VERSION ""

NS_ :

BS_:

BU_: ExternalDevice EMUS_BMS
BU_: INV U2C VCU BMS
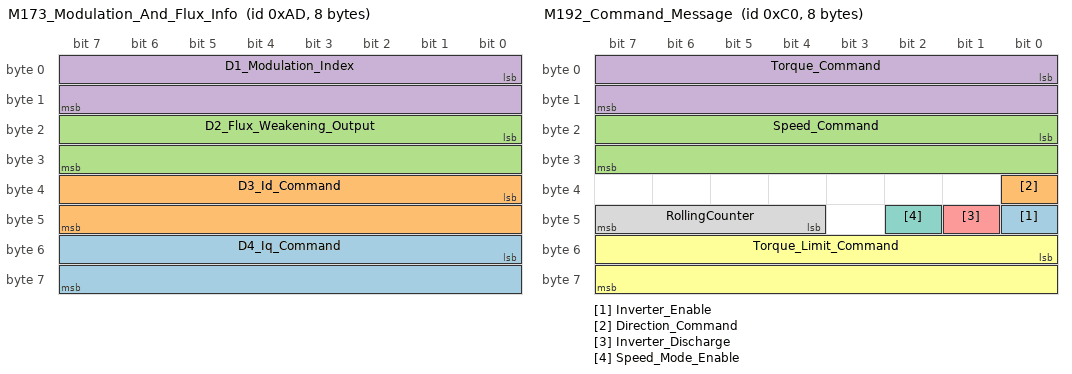
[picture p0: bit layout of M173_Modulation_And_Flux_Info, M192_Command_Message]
BO_ 173 M173_Modulation_And_Flux_Info: 8 INV
 SG_ D4_Iq_Command : 48|16@1- (0.1,0) [-3276.8|3276.7] "A" Vector__XXX
 SG_ D3_Id_Command : 32|16@1- (0.1,0) [-3276.8|3276.7] "A" Vector__XXX
 SG_ D2_Flux_Weakening_Output : 16|16@1- (0.1,0) [-3276.8|3276.7] "A" Vector__XXX
 SG_ D1_Modulation_Index : 0|16@1- (0.0001,0) [-3.2768|3.2767] "" Vector__XXX

BO_ 172 M172_Torque_And_Timer_Info: 8 INV
 SG_ D3_Power_On_Timer : 32|32@1+ (0.003,0) [0|12884800] "Sec" Vector__XXX
 SG_ D2_Torque_Feedback : 16|16@1- (0.1,0) [-3276.8|3276.7] "Nm" Vector__XXX
 SG_ D1_Commanded_Torque : 0|16@1- (0.1,0) [-3276.8|3276.7] "Nm" Vector__XXX

BO_ 194 M194_Read_Write_Param_Response: 8 INV
 SG_ D2_Write_Success : 16|1@1+ (1,0) [0|1] "" Vector__XXX
 SG_ D3_Data_Response : 32|16@1- (1,0) [-32768|32767] "" Vector__XXX
 SG_ D1_Parameter_Address_Response : 0|16@1+ (1,0) [0|65535] "" Vector__XXX

BO_ 193 M193_Read_Write_Param_Command: 8 VCU
 SG_ D3_Data_Command : 32|16@1- (1,0) [-32768|32767] "" Vector__XXX
 SG_ D2_Read_Write_Command : 16|1@1+ (1,0) [0|1] "" Vector__XXX
 SG_ D1_Parameter_Address_Command : 0|16@1+ (1,0) [0|65535] "" Vector__XXX

BO_ 192 M192_Command_Message: 8 VCU
 SG_ Inverter_Enable : 40|1@1+ (1,0) [0|1] "Bit" Vector__XXX
 SG_ Direction_Command : 32|1@1+ (1,0) [0|1] "Bit" Vector__XXX
 SG_ Speed_Command : 16|16@1- (1,0) [-32768|32767] "rpm" Vector__XXX
 SG_ Torque_Command : 0|16@1- (0.1,0) [-3276.8|3276.7] "Nm" Vector__XXX
 SG_ Inverter_Discharge : 41|1@1+ (1,0) [0|1] "Bit" Vector__XXX
 SG_ Torque_Limit_Command : 48|16@1- (0.1,0) [-3276.8|3276.7] "Nm" Vector__XXX
 SG_ Speed_Mode_Enable : 42|1@1+ (1,0) [0|1] "Bit" Vector__XXX
 SG_ RollingCounter : 44|4@1+ (1,0) [0|15] "Bits" Vector__XXX

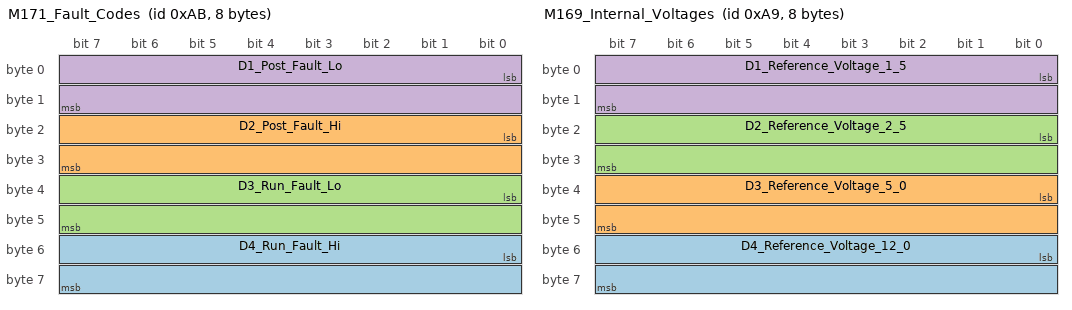
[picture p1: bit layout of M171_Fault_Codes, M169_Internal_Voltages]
BO_ 171 M171_Fault_Codes: 8 INV
 SG_ D4_Run_Fault_Hi : 48|16@1+ (1,0) [0|65535] "" Vector__XXX
 SG_ D2_Post_Fault_Hi : 16|16@1+ (1,0) [0|65535] "" Vector__XXX
 SG_ D3_Run_Fault_Lo : 32|16@1+ (1,0) [0|65535] "" Vector__XXX
 SG_ D1_Post_Fault_Lo : 0|16@1+ (1,0) [0|65535] "" Vector__XXX

BO_ 170 M170_Internal_States: 8 INV
 SG_ D7_Direction_Command : 56|1@1+ (1,0) [0|1] "" Vector__XXX
 SG_ D6_Inverter_Enable_State : 48|1@1+ (1,0) [0|1] "" Vector__XXX
 SG_ D3_Relay_3_Status : 26|1@1+ (1,0) [0|1] "" Vector__XXX
 SG_ D3_Relay_4_Status : 27|1@1+ (1,0) [0|1] "" Vector__XXX
 SG_ D3_Relay_2_Status : 25|1@1+ (1,0) [0|1] "" Vector__XXX
 SG_ D4_Inverter_Run_Mode : 32|1@1+ (1,0) [0|1] "" Vector__XXX
 SG_ D5_Inverter_Command_Mode : 40|1@1+ (1,0) [0|1] "" Vector__XXX
 SG_ D3_Relay_1_Status : 24|1@1+ (1,0) [0|1] "" Vector__XXX
 SG_ D2_Inverter_State : 16|8@1+ (1,0) [0|255] "" Vector__XXX
 SG_ D1_VSM_State : 0|8@1+ (1,0) [0|15] "" Vector__XXX
 SG_ D6_Inverter_Enable_Lockout : 55|1@1+ (1,0) [0|1] "" Vector__XXX
 SG_ D4_Inverter_Discharge_State : 37|3@1+ (1,0) [0|7] "" Vector__XXX
 SG_ D3_Relay_5_Status : 28|1@1+ (1,0) [0|1] "" Vector__XXX
 SG_ D3_Relay_6_Status : 29|1@1+ (1,0) [0|1] "" Vector__XXX
 SG_ D7_BMS_Active : 57|1@1+ (1,0) [0|1] "" Vector__XXX
 SG_ D7_BMS_Torque_Limiting : 58|1@1+ (1,0) [0|1] "" Vector__XXX
 SG_ D7_Max_Speed_Limiting : 59|1@1+ (1,0) [0|1] "" Vector__XXX
 SG_ D7_Low_Speed_Limiting : 61|1@1+ (1,0) [0|1] "" Vector__XXX
 SG_ D5_Rolling_Counter : 44|4@1+ (1,0) [0|15] "" Vector__XXX
 SG_ D1_PWM_Frequency : 8|8@1+ (1,0) [0|255] "kHz" Vector__XXX
 SG_ D6_Start_Mode_Active : 54|1@1+ (1,0) [0|1] "" Vector__XXX

BO_ 169 M169_Internal_Voltages: 8 INV
 SG_ D4_Reference_Voltage_12_0 : 48|16@1- (0.01,0) [-327.68|327.67] "V" Vector__XXX
 SG_ D3_Reference_Voltage_5_0 : 32|16@1- (0.01,0) [-327.68|327.67] "V" Vector__XXX
 SG_ D2_Reference_Voltage_2_5 : 16|16@1- (0.01,0) [-327.68|327.67] "V" Vector__XXX
 SG_ D1_Reference_Voltage_1_5 : 0|16@1- (0.01,0) [-327.68|327.67] "V" Vector__XXX

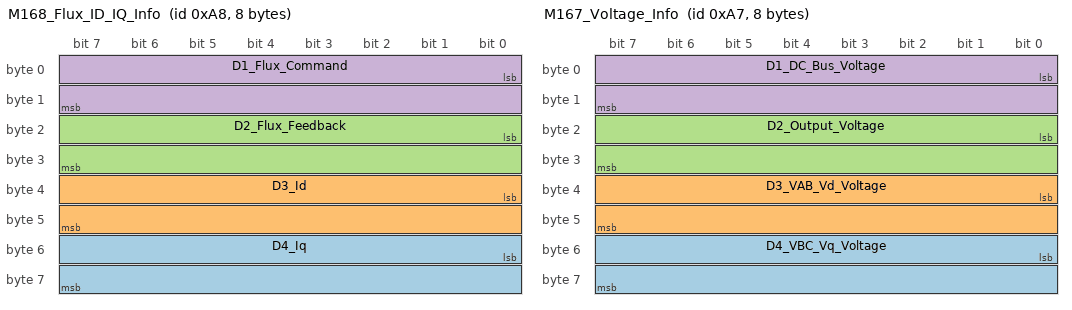
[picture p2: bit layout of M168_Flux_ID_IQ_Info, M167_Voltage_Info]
BO_ 168 M168_Flux_ID_IQ_Info: 8 INV
 SG_ D4_Iq : 48|16@1- (0.1,0) [-3276.8|3276.7] "A" Vector__XXX
 SG_ D3_Id : 32|16@1- (0.1,0) [-3276.8|3276.7] "A" Vector__XXX
 SG_ D2_Flux_Feedback : 16|16@1- (0.001,0) [-32.768|32.767] "Wb" Vector__XXX
 SG_ D1_Flux_Command : 0|16@1- (0.001,0) [-32.768|32.767] "Wb" Vector__XXX

BO_ 167 M167_Voltage_Info: 8 INV
 SG_ D4_VBC_Vq_Voltage : 48|16@1- (0.1,0) [-3276.8|3276.7] "V" Vector__XXX
 SG_ D3_VAB_Vd_Voltage : 32|16@1- (0.1,0) [-3276.8|3276.7] "V" Vector__XXX
 SG_ D2_Output_Voltage : 16|16@1- (0.1,0) [-3276.8|3276.7] "V" Vector__XXX
 SG_ D1_DC_Bus_Voltage : 0|16@1- (0.1,0) [-3276.8|3276.7] "V" Vector__XXX

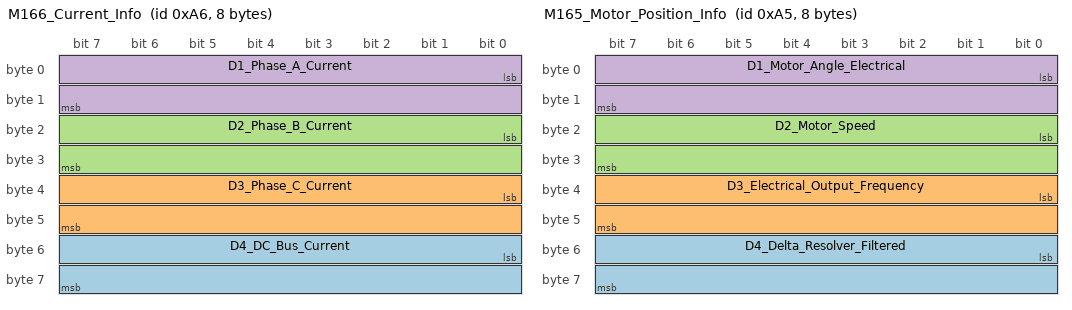
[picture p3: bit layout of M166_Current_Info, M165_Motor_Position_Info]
BO_ 166 M166_Current_Info: 8 INV
 SG_ D4_DC_Bus_Current : 48|16@1- (0.1,0) [-3276.8|3276.7] "A" Vector__XXX
 SG_ D3_Phase_C_Current : 32|16@1- (0.1,0) [-3276.8|3276.7] "A" Vector__XXX
 SG_ D2_Phase_B_Current : 16|16@1- (0.1,0) [-3276.8|3276.7] "A" Vector__XXX
 SG_ D1_Phase_A_Current : 0|16@1- (0.1,0) [-3276.8|3276.7] "A" Vector__XXX

BO_ 165 M165_Motor_Position_Info: 8 INV
 SG_ D4_Delta_Resolver_Filtered : 48|16@1- (0.1,0) [-3276.8|3276.7] "deg" Vector__XXX
 SG_ D3_Electrical_Output_Frequency : 32|16@1- (0.1,0) [-3276.8|3276.7] "hz" Vector__XXX
 SG_ D2_Motor_Speed : 16|16@1- (1,0) [-32768|32767] "rpm" Vector__XXX
 SG_ D1_Motor_Angle_Electrical : 0|16@1+ (0.1,0) [0|6553.5] "deg" Vector__XXX

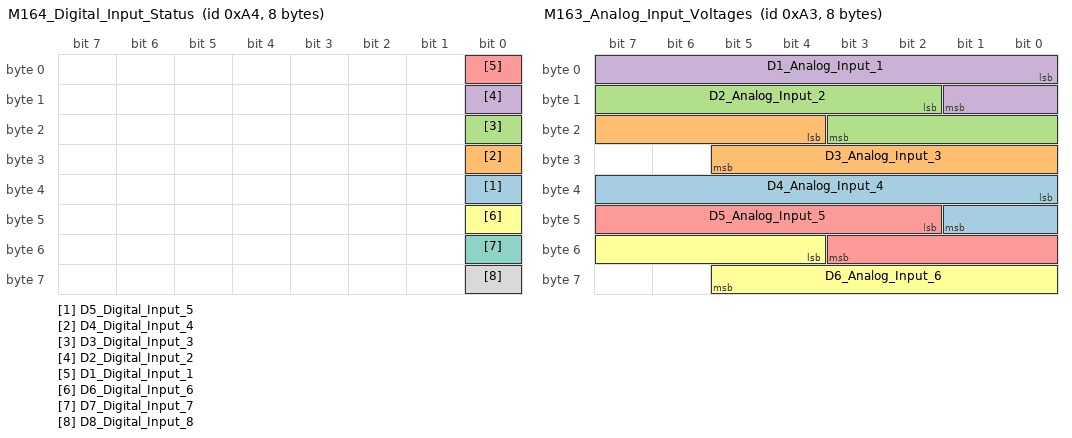
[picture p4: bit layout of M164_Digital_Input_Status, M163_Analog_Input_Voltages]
BO_ 164 M164_Digital_Input_Status: 8 INV
 SG_ D5_Digital_Input_5 : 32|1@1+ (1,0) [0|1] "boolean" Vector__XXX
 SG_ D4_Digital_Input_4 : 24|1@1+ (1,0) [0|1] "boolean" Vector__XXX
 SG_ D3_Digital_Input_3 : 16|1@1+ (1,0) [0|1] "boolean" Vector__XXX
 SG_ D2_Digital_Input_2 : 8|1@1+ (1,0) [0|1] "boolean" Vector__XXX
 SG_ D1_Digital_Input_1 : 0|1@1+ (1,0) [0|1] "boolean" Vector__XXX
 SG_ D6_Digital_Input_6 : 40|1@1+ (1,0) [0|1] "boolean" Vector__XXX
 SG_ D7_Digital_Input_7 : 48|1@1+ (1,0) [0|1] "boolean" Vector__XXX
 SG_ D8_Digital_Input_8 : 56|1@1+ (1,0) [0|1] "boolean" Vector__XXX

BO_ 163 M163_Analog_Input_Voltages: 8 INV
 SG_ D4_Analog_Input_4 : 32|10@1+ (0.01,0) [0|10.23] "V" Vector__XXX
 SG_ D3_Analog_Input_3 : 20|10@1+ (0.01,0) [0|10.23] "V" Vector__XXX
 SG_ D2_Analog_Input_2 : 10|10@1+ (0.01,0) [0|10.23] "V" Vector__XXX
 SG_ D1_Analog_Input_1 : 0|10@1+ (0.01,0) [0|10.23] "V" Vector__XXX
 SG_ D5_Analog_Input_5 : 42|10@1+ (0.01,0) [0|10.23] "V" Vector__XXX
 SG_ D6_Analog_Input_6 : 52|10@1+ (0.01,0) [0|10.23] "V" Vector__XXX

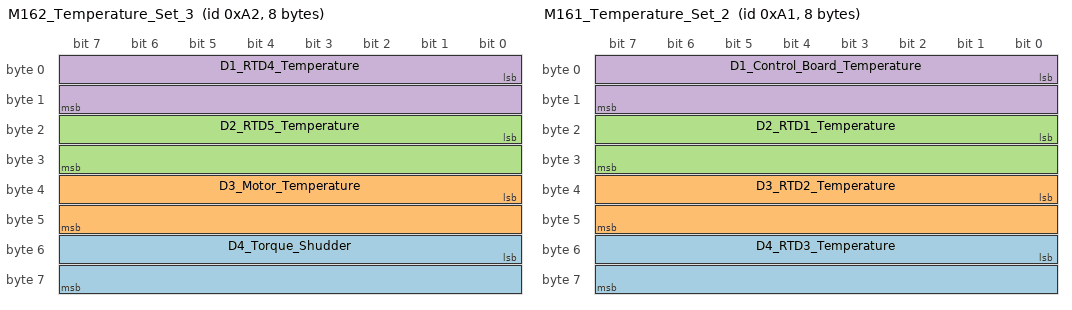
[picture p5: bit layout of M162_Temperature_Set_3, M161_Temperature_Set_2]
BO_ 162 M162_Temperature_Set_3: 8 INV
 SG_ D4_Torque_Shudder : 48|16@1- (0.1,0) [-3276.8|3276.7] "Nm" Vector__XXX
 SG_ D3_Motor_Temperature : 32|16@1- (0.1,0) [-3276.8|3276.7] "degC" Vector__XXX
 SG_ D2_RTD5_Temperature : 16|16@1- (0.1,0) [-3276.8|3276.7] "degC" Vector__XXX
 SG_ D1_RTD4_Temperature : 0|16@1- (0.1,0) [-3276.8|3276.7] "degC" Vector__XXX

BO_ 161 M161_Temperature_Set_2: 8 INV
 SG_ D4_RTD3_Temperature : 48|16@1- (0.1,0) [-3276.8|3276.7] "degC" Vector__XXX
 SG_ D3_RTD2_Temperature : 32|16@1- (0.1,0) [-3276.8|3276.7] "degC" Vector__XXX
 SG_ D2_RTD1_Temperature : 16|16@1- (0.1,0) [-3276.8|3276.7] "degC" Vector__XXX
 SG_ D1_Control_Board_Temperature : 0|16@1- (0.1,0) [-3276.8|3276.7] "degC" Vector__XXX

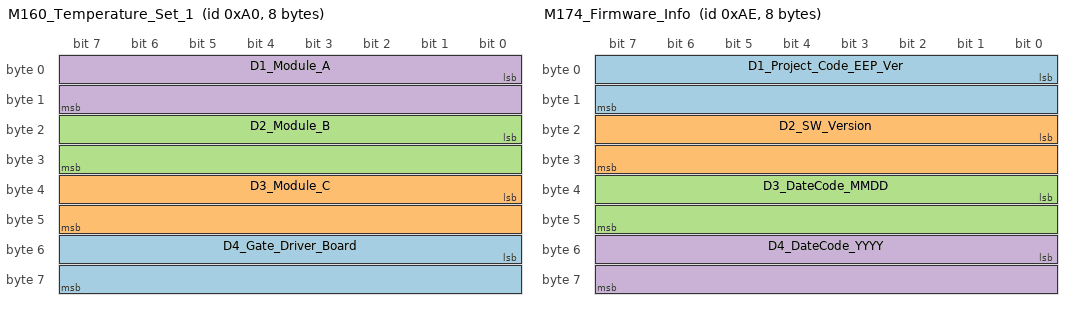
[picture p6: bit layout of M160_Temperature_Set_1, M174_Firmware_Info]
BO_ 160 M160_Temperature_Set_1: 8 INV
 SG_ D4_Gate_Driver_Board : 48|16@1- (0.1,0) [-3276.8|3276.7] "degC" Vector__XXX
 SG_ D3_Module_C : 32|16@1- (0.1,0) [-3276.8|3276.7] "degC" Vector__XXX
 SG_ D2_Module_B : 16|16@1- (0.1,0) [-3276.8|3276.7] "degC" Vector__XXX
 SG_ D1_Module_A : 0|16@1- (0.1,0) [-3276.8|3276.7] "degC" Vector__XXX

BO_ 174 M174_Firmware_Info: 8 INV
 SG_ D1_Project_Code_EEP_Ver : 0|16@1+ (1,0) [0|65535] "" Vector__XXX
 SG_ D2_SW_Version : 16|16@1+ (1,0) [0|65535] "" Vector__XXX
 SG_ D3_DateCode_MMDD : 32|16@1+ (1,0) [0|65535] "" Vector__XXX
 SG_ D4_DateCode_YYYY : 48|16@1+ (1,0) [0|65535] "" Vector__XXX

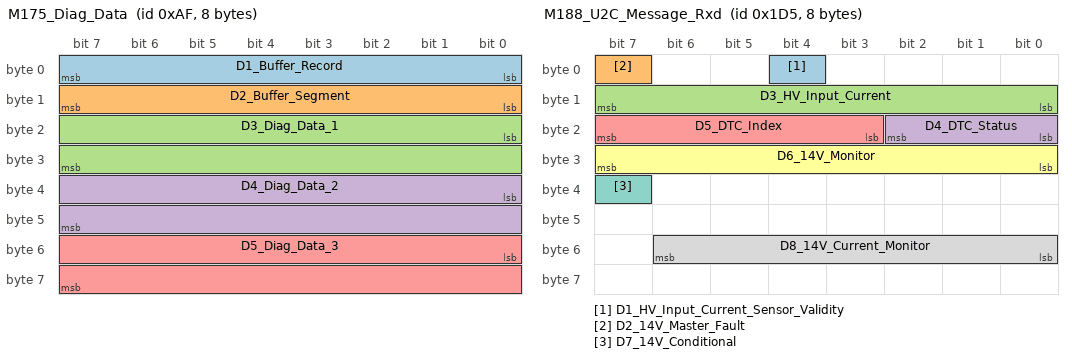
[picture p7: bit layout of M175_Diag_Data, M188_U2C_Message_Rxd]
BO_ 175 M175_Diag_Data: 8 INV
 SG_ D1_Buffer_Record : 0|8@1+ (1,0) [0|255] "" Vector__XXX
 SG_ D2_Buffer_Segment : 8|8@1+ (1,0) [0|5] "" Vector__XXX
 SG_ D3_Diag_Data_1 : 16|16@1- (1,0) [-32768|32767] "" Vector__XXX
 SG_ D4_Diag_Data_2 : 32|16@1- (1,0) [-32768|32767] "" Vector__XXX
 SG_ D5_Diag_Data_3 : 48|16@1- (1,0) [-32768|32767] "" Vector__XXX

BO_ 471 M187_U2C_Command_Txd: 8 INV
 SG_ D1_ID_Byte : 0|8@1+ (1,0) [0|255] "" Vector__XXX
 SG_ D2_Setpoint_Calc : 8|8@1+ (1,0) [0|255] "" Vector__XXX

BO_ 469 M188_U2C_Message_Rxd: 8 U2C
 SG_ D1_HV_Input_Current_Sensor_Validity : 4|1@1+ (1,0) [0|1] "" Vector__XXX
 SG_ D2_14V_Master_Fault : 7|1@1+ (1,0) [0|1] "" Vector__XXX
 SG_ D3_HV_Input_Current : 8|8@1+ (1,0) [0|255] "" Vector__XXX
 SG_ D4_DTC_Status : 16|3@1+ (1,0) [0|7] "" Vector__XXX
 SG_ D5_DTC_Index : 19|5@1+ (1,0) [0|31] "" Vector__XXX
 SG_ D6_14V_Monitor : 24|8@1+ (1,0) [0|255] "" Vector__XXX
 SG_ D7_14V_Conditional : 39|1@1+ (1,0) [0|1] "" Vector__XXX
 SG_ D8_14V_Current_Monitor : 48|7@1+ (1,0) [0|127] "" Vector__XXX

BO_ 514 BMS_Current_Limit: 8 BMS
 SG_ D1_Max_Discharge_Current : 0|16@1+ (1,0) [0|1000] "A" Vector__XXX
 SG_ D2_Max_Charge_Current : 16|16@1+ (1,0) [0|1000] "A" Vector__XXX

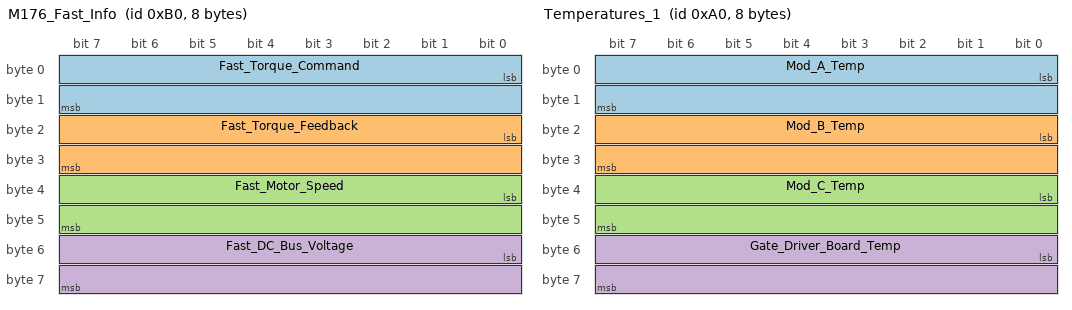
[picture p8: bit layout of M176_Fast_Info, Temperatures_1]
BO_ 176 M176_Fast_Info: 8 INV
 SG_ Fast_Torque_Command : 0|16@1- (0.1,0) [-3276.8|3276.7] "Nm" Vector__XXX
 SG_ Fast_Torque_Feedback : 16|16@1- (0.1,0) [-3276.8|3276.7] "Nm" Vector__XXX
 SG_ Fast_Motor_Speed : 32|16@1- (1,0) [-32768|32767] "rpm" Vector__XXX
 SG_ Fast_DC_Bus_Voltage : 48|16@1- (0.1,0) [-3276.8|3276.7] "V" Vector__XXX

BO_ 160 Temperatures_1: 8 Vector__XXX
	SG_ Mod_A_Temp : 0|16@1- (0.1,0) [-3276.8|3276.7] "C" Vector__XXX
	SG_ Mod_B_Temp : 16|16@1- (0.1,0) [-3276.8|3276.7] "C" Vector__XXX
	SG_ Mod_C_Temp : 32|16@1- (0.1,0) [-3276.8|3276.7] "C" Vector__XXX
	SG_ Gate_Driver_Board_Temp : 48|16@1- (0.1,0) [-3276.8|3276.7] "C" Vector__XXX

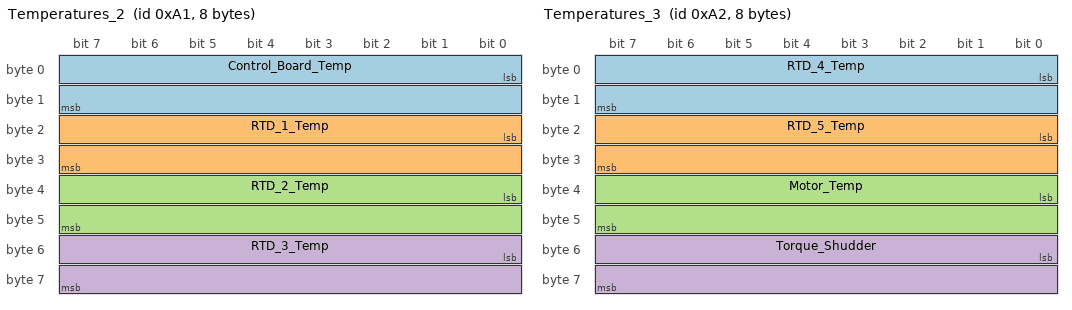
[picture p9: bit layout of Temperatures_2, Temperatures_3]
BO_ 161 Temperatures_2: 8 Vector__XXX
	SG_ Control_Board_Temp : 0|16@1- (0.1,0) [-3276.8|3276.7] "C" Vector__XXX
	SG_ RTD_1_Temp : 16|16@1- (0.1,0) [-3276.8|3276.7] "C" Vector__XXX
	SG_ RTD_2_Temp : 32|16@1- (0.1,0) [-3276.8|3276.7] "C" Vector__XXX
	SG_ RTD_3_Temp : 48|16@1- (0.1,0) [-3276.8|3276.7] "C" Vector__XXX

BO_ 162 Temperatures_3: 8 Vector__XXX
	SG_ RTD_4_Temp : 0|16@1- (0.1,0) [-3276.8|3276.7] "C" Vector__XXX
	SG_ RTD_5_Temp : 16|16@1- (0.1,0) [-3276.8|3276.7] "C" Vector__XXX
	SG_ Motor_Temp : 32|16@1- (0.1,0) [-3276.8|3276.7] "C" Vector__XXX
	SG_ Torque_Shudder : 48|16@1- (0.1,0) [-3276.8|3276.7] "N*m" Vector__XXX

BO_ 165 Motor_Position_Info: 8 Vector__XXX
	SG_ Motor_Angle_Electrical : 0|16@1- (0.1,0) [-359.9|359.9] "degrees" Vector__XXX
	SG_ Motor_Speed : 16|16@1- (0.1,0) [-32768|32767] "rpm" Vector__XXX
	SG_ Electrical_Output_Freq : 32|16@1- (0.1,0) [-3276.8|3276.7] "Hz" Vector__XXX
	SG_ Delta_Resolver_Filtered : 48|16@1- (0.1,0) [-359.9|359.9] "degrees" Vector__XXX

BO_ 2148139011 Accelerometer: 6 Vector__XXX
	SG_ X_Axis_Acceleration : 7|16@0- (0.000244141,0) [-8|8] "g" Vector__XXX
	SG_ Y_Axis_Acceleration : 23|16@0- (0.000244141,0) [-8|8] "g" Vector__XXX
	SG_ Z_Axis_Acceleration : 39|16@0- (0.000244141,0) [-8|8] "g" Vector__XXX

BO_ 2148139012 Yaw_Rate: 6 Vector__XXX
	SG_ X_Axis_YawRate : 7|16@0- (0.015258789,0) [-500|500] "deg/s" Vector__XXX
	SG_ Y_Axis_YawRate : 23|16@0- (0.015258789,0) [-500|500] "deg/s" Vector__XXX
	SG_ Z_Axis_YawRate : 39|16@0- (0.015258789,0) [-500|500] "deg/s" Vector__XXX

BO_ 2148139008 GPS_Position: 8 Vector__XXX
	SG_ GPS_Latitude : 7|32@0- (1,0) [-180|180] "degrees" Vector__XXX
	SG_ GPS_Longitude : 39|32@0- (1,0) [-180|180] "degrees" Vector__XXX

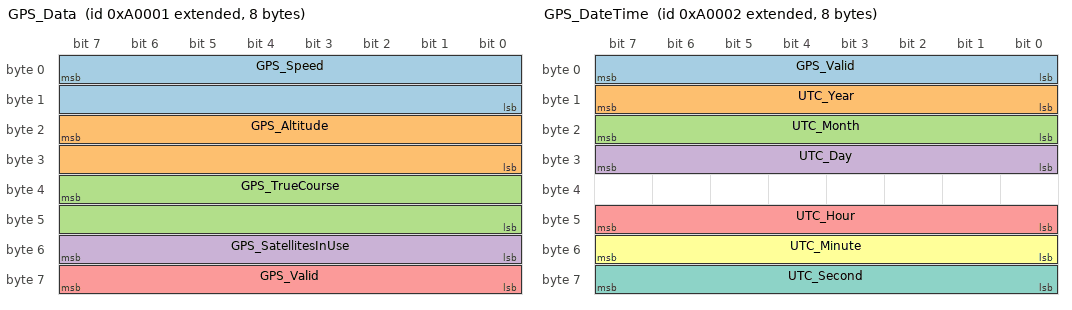
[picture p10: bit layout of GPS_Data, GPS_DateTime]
BO_ 2148139009 GPS_Data: 8 Vector__XXX
	SG_ GPS_Speed : 7|16@0+ (0.01,0) [0|655.35] "mph" Vector__XXX
	SG_ GPS_Altitude : 23|16@0- (1,0) [-32768|32767] "ft" Vector__XXX
	SG_ GPS_TrueCourse : 39|16@0+ (0.01,0) [0|655.35] "degrees" Vector__XXX
	SG_ GPS_SatellitesInUse : 55|8@0+ (1,0) [0|255] "satellites" Vector__XXX
	SG_ GPS_Valid : 63|8@0+ (1,0) [0|255] "OK(1)/N(2)" Vector__XXX

BO_ 2148139010 GPS_DateTime: 8 Vector__XXX
	SG_ GPS_Valid : 7|8@0+ (1,0) [0|255] "OK(1)/N(2)" Vector__XXX
	SG_ UTC_Year : 15|8@0+ (1,0) [0|255] "year" Vector__XXX
	SG_ UTC_Month : 23|8@0+ (1,0) [0|255] "month" Vector__XXX
	SG_ UTC_Day : 31|8@0+ (1,0) [0|255] "day" Vector__XXX
	SG_ UTC_Hour : 47|8@0+ (1,0) [0|255] "hour" Vector__XXX
	SG_ UTC_Minute : 55|8@0+ (1,0) [0|255] "min" Vector__XXX
	SG_ UTC_Second : 63|8@0+ (1,0) [0|255] "sec" Vector__XXX

BU_: ExternalDevice EMUS_BMS

BO_ 2578777872 Serial_Number_Ext: 4 EMUS_BMS
 SG_ Serial_Number_Number : 7|32@0+ (1,0) [0|4294967295] "" Vector__XXX

BO_ 3 Serial_Number_Std: 4 EMUS_BMS
 SG_ Serial_Number_Number : 7|32@0+ (1,0) [0|4294967295] "" Vector__XXX

BO_ 2 Version_Std: 6 EMUS_BMS
 SG_ Version_PatchVersion : 39|16@0+ (1,0) [0|65535] "" Vector__XXX
 SG_ Version_RevisionVersion : 16|8@1+ (1,0) [0|255] "" Vector__XXX
 SG_ Version_MinorVersion : 8|8@1+ (1,0) [0|255] "" Vector__XXX
 SG_ Version_MajorVersion : 0|8@1+ (1,0) [0|255] "" Vector__XXX

BO_ 2578777856 Version_Ext: 6 EMUS_BMS
 SG_ Version_PatchVersion : 39|16@0+ (1,0) [0|65535] "" Vector__XXX
 SG_ Version_RevisionVersion : 16|8@1+ (1,0) [0|255] "" Vector__XXX
 SG_ Version_MinorVersion : 8|8@1+ (1,0) [0|255] "" Vector__XXX
 SG_ Version_MajorVersion : 0|8@1+ (1,0) [0|255] "" Vector__XXX

BO_ 571 Reset_BMS_Std: 8 ExternalDevice

BO_ 2578777094 Reset_BMS_Ext: 8 ExternalDevice

BO_ 2578776070 Energy_Parameters_2_Ext: 8 EMUS_BMS
 SG_ Energy_EstimatedConsumption : 7|16@0+ (1,0) [0|65535] "Wh" Vector__XXX
 SG_ Energy_EstimatedEnergy : 23|16@0+ (0.01,0) [0|655.35] "kWh" Vector__XXX
 SG_ Energy_EstimatedDistanceLeft : 39|16@0+ (0.1,0) [0|6553.5] "" Vector__XXX
 SG_ Energy_DistanceTraveled : 55|16@0+ (0.1,0) [0|6553.5] "" Vector__XXX

BO_ 2578776069 State_Of_Charge_2_Param_Ext: 8 EMUS_BMS
 SG_ SOCParams_Current : 7|16@0+ (0.1,0) [0|6553.5] "A" Vector__XXX
 SG_ SOCParams_EstimatedCharge : 23|16@0+ (1,0) [0|65535] "W/V" Vector__XXX
 SG_ SOCParams_EstimatedSOC : 48|8@1+ (1,0) [0|255] "" Vector__XXX
 SG_ SOC_Params_EstimatedSOH : 56|8@1+ (1,0) [0|255] "" Vector__XXX

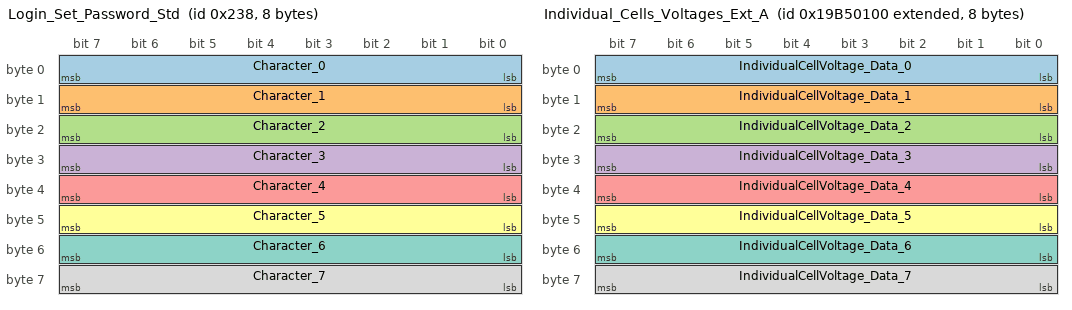
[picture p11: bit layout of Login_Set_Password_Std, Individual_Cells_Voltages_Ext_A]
BO_ 568 Login_Set_Password_Std: 8 ExternalDevice
 SG_ Character_0 : 0|8@1+ (1,0) [0|255] "" Vector__XXX
 SG_ Character_1 : 8|8@1+ (1,0) [0|255] "" Vector__XXX
 SG_ Character_2 : 16|8@1+ (1,0) [0|255] "" Vector__XXX
 SG_ Character_3 : 24|8@1+ (1,0) [0|255] "" Vector__XXX
 SG_ Character_4 : 32|8@1+ (1,0) [0|255] "" Vector__XXX
 SG_ Character_5 : 40|8@1+ (1,0) [0|255] "" Vector__XXX
 SG_ Character_6 : 48|8@1+ (1,0) [0|255] "" Vector__XXX
 SG_ Character_7 : 56|8@1+ (1,0) [0|255] "" Vector__XXX

BO_ 2578776065 Battery_Volt_Overall_Param_Ext: 8 EMUS_BMS
 SG_ VoltOverallParams_TotalVolt : 31|32@0+ (0.01,0) [0|42949672.95] "V" Vector__XXX
 SG_ VoltOverallParam_MinCellVoltage : 0|8@1+ (0.01,2) [2|4.55] "V" Vector__XXX
 SG_ VoltOverallParam_MaxCellVoltage : 8|8@1+ (0.01,2) [2|4.55] "V" Vector__XXX
 SG_ VoltOverallParam_AvrgCellVoltage : 16|8@1+ (0.01,2) [2|4.55] "V" Vector__XXX

BO_ 2578776064 Overall_Parameters_Ext: 8 EMUS_BMS
 SG_ OverallParams_IgnitionKey : 0|1@1+ (1,0) [0|1] "" Vector__XXX
 SG_ OverallParams_ChargerMains : 1|1@1+ (1,0) [0|1] "" Vector__XXX
 SG_ OverallParams_FastCharge : 2|1@1+ (1,0) [0|1] "" Vector__XXX
 SG_ OverallParams_LeakageSensor : 3|1@1+ (1,0) [0|1] "" Vector__XXX
 SG_ OverallParams_ChargerEnable : 8|1@1+ (1,0) [0|1] "" Vector__XXX
 SG_ OverallParams_HeaterEnable : 9|1@1+ (1,0) [0|1] "" Vector__XXX
 SG_ OverallParams_BatteryContactor : 10|1@1+ (1,0) [0|1] "" Vector__XXX
 SG_ OverallParams_BatteryFan : 11|1@1+ (1,0) [0|1] "" Vector__XXX
 SG_ OverallParams_PowerReduction : 12|1@1+ (1,0) [0|1] "" Vector__XXX
 SG_ OverallParams_DCDC_Control : 14|1@1+ (1,0) [0|1] "" Vector__XXX
 SG_ OverallParams_ContactorPreCharge : 15|1@1+ (1,0) [0|1] "" Vector__XXX
 SG_ OverallParams_NumberOfCells_MSB : 16|8@1+ (1,0) [0|255] "" Vector__XXX
 SG_ OverallParams_ChargingStage : 24|8@1+ (1,0) [0|255] "" Vector__XXX
 SG_ OverallParams_ChrgStageDurat_MSB : 32|8@1+ (1,0) [0|255] "" Vector__XXX
 SG_ OverallParams_LastChargingError : 48|8@1+ (1,0) [0|255] "" Vector__XXX
 SG_ OverallParams_ChargingInterlock : 13|1@1+ (1,0) [0|1] "" Vector__XXX
 SG_ OverallParams_ChrgStageDurat_LSB : 40|8@1+ (1,0) [0|255] "" Vector__XXX
 SG_ OverallParams_NumberOfCells_LSB : 56|8@1+ (1,0) [0|255] "" Vector__XXX

BO_ 2578776071 Diagnostic_Codes_Ext: 8 EMUS_BMS
 SG_ DiagnosticCodes_UnderVoltage : 0|1@1+ (1,0) [0|1] "" Vector__XXX
 SG_ DiagnosticCodes_OverVoltage : 1|1@1+ (1,0) [0|1] "" Vector__XXX
 SG_ DiagnosticCodes_DchrgOvrCurrent : 2|1@1+ (1,0) [0|1] "" Vector__XXX
 SG_ DiagnosticCodes_ChrgOverCurrent : 3|1@1+ (1,0) [0|1] "" Vector__XXX
 SG_ DiagnosticCodes_CellModOverHeat : 4|1@1+ (1,0) [0|1] "" Vector__XXX
 SG_ DiagnosticCodes_Leakage : 5|1@1+ (1,0) [0|1] "" Vector__XXX
 SG_ DiagnosticCodes_NoCellComm : 6|1@1+ (1,0) [0|1] "" Vector__XXX
 SG_ DiagnosticCodes_LowVoltage : 8|1@1+ (1,0) [0|1] "" Vector__XXX
 SG_ DiagnosticCodes_HighCurrent : 9|1@1+ (1,0) [0|1] "" Vector__XXX
 SG_ DiagnosticCodes_HighCellModTemp : 10|1@1+ (1,0) [0|1] "" Vector__XXX
 SG_ DiagnosticCodes_CellOverHeat : 19|1@1+ (1,0) [0|1] "" Vector__XXX
 SG_ DiagnosticCodes_NoCurrentSensor : 20|1@1+ (1,0) [0|1] "" Vector__XXX
 SG_ DiagnosticCodes_PackUnderVoltage : 21|1@1+ (1,0) [0|1] "" Vector__XXX
 SG_ DiagnosticCodes_CellVoltValidity : 24|1@1+ (1,0) [0|1] "" Vector__XXX
 SG_ DiagnosticCodes_CellModTempValid : 25|1@1+ (1,0) [0|1] "" Vector__XXX
 SG_ DiagnosticCodes_CellBalancValid : 26|1@1+ (1,0) [0|1] "" Vector__XXX
 SG_ DiagnosticCodes_NumOfCellsValid : 27|1@1+ (1,0) [0|1] "" Vector__XXX
 SG_ DiagnosticCodes_BatChrgFinished : 28|1@1+ (1,0) [0|1] "" Vector__XXX
 SG_ DiagnosticCodes_CellTempValid : 29|1@1+ (1,0) [0|1] "" Vector__XXX
 SG_ DiagnosticCodes_MS_ConfError : 7|1@1+ (1,0) [0|1] "" Vector__XXX
 SG_ DiagnosticCodes_MSConfigMismatch : 11|1@1+ (1,0) [0|1] "" Vector__XXX
 SG_ DiagnosticCodes_MSComMalfunc : 12|1@1+ (1,0) [0|1] "" Vector__XXX
 SG_ DiagnosticCodes_HighCellTemp : 13|1@1+ (1,0) [0|1] "" Vector__XXX
 SG_ DiagnosticCodes_MSIntCANError : 16|1@1+ (1,0) [0|1] "" Vector__XXX
 SG_ DiagnosticCodes_MSCommCANFail : 17|1@1+ (1,0) [0|1] "" Vector__XXX
 SG_ DiagnosticCodes_ACPresnce : 18|1@1+ (1,0) [0|1] "" Vector__XXX

BO_ 2578776066 Cell_Mod_Temp_Overall_Param_Ext: 8 EMUS_BMS
 SG_ CellModOverallPar_MinCellModTemp : 0|8@1+ (1,-100) [-100|155] "�C" Vector__XXX
 SG_ CellModOverallPar_MaxCellModTemp : 8|8@1+ (1,-100) [-100|155] "�C" Vector__XXX
 SG_ CellModOverallPar_AvgCellModTemp : 16|8@1+ (1,-100) [-100|155] "�C" Vector__XXX

BO_ 2578776072 Cell_Temp_Overall_Params_Ext: 8 EMUS_BMS
 SG_ CellOverallPar_AvgCellTemp : 16|8@1+ (1,-100) [-100|155] "�C" Vector__XXX
 SG_ CellOverallPar_MaxCellTemp : 8|8@1+ (1,-100) [-100|155] "�C" Vector__XXX
 SG_ CellOverallPar_MinCellTemp : 0|8@1+ (1,-100) [-100|155] "�C" Vector__XXX

BO_ 2578776067 Cell_Balanc_Rate_Overall_Par_Ext: 8 EMUS_BMS
 SG_ CellBalancPar_MinCellBalancRate : 0|8@1+ (0.392156862745098,0) [0|100] "%" Vector__XXX
 SG_ CellBalancPar_MaxCellBalancRate : 8|8@1+ (0.392156862745098,0) [0|100] "%" Vector__XXX
 SG_ CellBalancPar_AvgCellBalancRate : 16|8@1+ (0.392156862745098,0) [0|100] "%" Vector__XXX

BO_ 2578777088 Configuration_Parameters_Ext: 8 EMUS_BMS
 SG_ ConfigParams_ParameterID : 7|16@0+ (1,0) [0|65535] "" Vector__XXX
 SG_ ConfigParams_ParameterSize : 16|8@1+ (1,0) [0|255] "" Vector__XXX
 SG_ ConfigParams_ParameterData : 31|32@0+ (1,0) [0|4294967295] "" Vector__XXX

BO_ 2578777090 Login_Level_Ext: 8 EMUS_BMS
 SG_ LoginLevel : 0|8@1+ (1,0) [0|255] "" Vector__XXX

BO_ 2578777089 Contactor_Control_Ext: 8 ExternalDevice
 SG_ ContactorControl_ContactorState : 0|8@1+ (1,0) [0|255] "" Vector__XXX

BO_ 2578777600 Energy_Parameters_Ext: 8 EMUS_BMS
 SG_ Energy_DistanceTraveled : 55|16@0+ (0.1,0) [0|6553.5] "" Vector__XXX
 SG_ Energy_EstimatedDistanceLeft : 39|16@0+ (0.1,0) [0|6553.5] "" Vector__XXX
 SG_ Energy_EstimatedEnergy : 23|16@0+ (0.01,0) [0|655.35] "kWh" Vector__XXX
 SG_ Energy_EstimatedConsumption : 7|16@0+ (1,0) [0|65535] "Wh" Vector__XXX

BO_ 2578777344 State_Of_Charge_Param_Ext: 8 EMUS_BMS
 SG_ SOC_Params_EstimatedSOH : 40|8@1+ (1,0) [0|255] "" Vector__XXX
 SG_ SOCParams_EstimatedSOC : 32|8@1+ (1,0) [0|255] "" Vector__XXX
 SG_ SOCParams_EstimatedCharge : 23|16@0+ (1,0) [0|65535] "W/V" Vector__XXX
 SG_ SOCParams_Current : 7|16@0+ (0.1,0) [0|6553.5] "A" Vector__XXX

BO_ 2578777092 Statistics_Ext: 8 EMUS_BMS
 SG_ Statistics_Identifier : 0|8@1+ (1,0) [0|255] "" Vector__XXX
 SG_ Statistics_DataType : 8|8@1+ (1,0) [0|255] "" Vector__XXX
 SG_ Statistics_Data : 23|32@0+ (1,0) [0|4294967295] "" Vector__XXX

BO_ 2578777093 Events_Ext: 8 EMUS_BMS
 SG_ Events_EntryNumber : 0|8@1+ (1,0) [0|255] "" Vector__XXX
 SG_ Events_DataType : 8|8@1+ (1,0) [0|255] "" Vector__XXX
 SG_ Events_Data : 23|32@0+ (1,0) [0|4294967295] "" Vector__XXX

BO_ 2578776320 Individual_Cells_Voltages_Ext_A: 8 EMUS_BMS
 SG_ IndividualCellVoltage_Data_0 : 0|8@1+ (0.01,2) [2|4.55] "V" Vector__XXX
 SG_ IndividualCellVoltage_Data_1 : 8|8@1+ (0.01,2) [2|4.55] "V" Vector__XXX
 SG_ IndividualCellVoltage_Data_2 : 16|8@1+ (0.01,2) [2|4.55] "V" Vector__XXX
 SG_ IndividualCellVoltage_Data_3 : 24|8@1+ (0.01,2) [2|4.55] "V" Vector__XXX
 SG_ IndividualCellVoltage_Data_4 : 32|8@1+ (0.01,2) [2|4.55] "V" Vector__XXX
 SG_ IndividualCellVoltage_Data_5 : 40|8@1+ (0.01,2) [2|4.55] "V" Vector__XXX
 SG_ IndividualCellVoltage_Data_6 : 48|8@1+ (0.01,2) [2|4.55] "V" Vector__XXX
 SG_ IndividualCellVoltage_Data_7 : 56|8@1+ (0.01,2) [2|4.55] "V" Vector__XXX

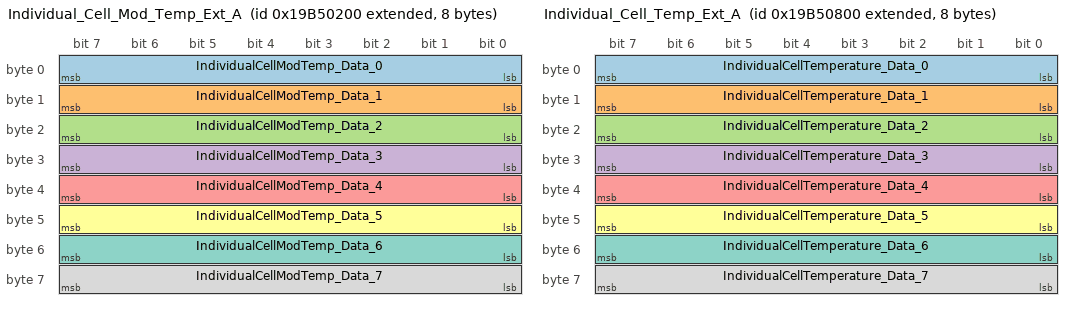
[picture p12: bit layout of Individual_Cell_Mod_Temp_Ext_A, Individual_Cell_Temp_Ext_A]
BO_ 2578776576 Individual_Cell_Mod_Temp_Ext_A: 8 EMUS_BMS
 SG_ IndividualCellModTemp_Data_0 : 0|8@1+ (1,-100) [-100|155] "�C" Vector__XXX
 SG_ IndividualCellModTemp_Data_1 : 8|8@1+ (1,-100) [-100|155] "�C" Vector__XXX
 SG_ IndividualCellModTemp_Data_2 : 16|8@1+ (1,-100) [-100|155] "�C" Vector__XXX
 SG_ IndividualCellModTemp_Data_3 : 24|8@1+ (1,-100) [-100|155] "�C" Vector__XXX
 SG_ IndividualCellModTemp_Data_4 : 32|8@1+ (1,-100) [-100|155] "�C" Vector__XXX
 SG_ IndividualCellModTemp_Data_5 : 40|8@1+ (1,-100) [-100|155] "�C" Vector__XXX
 SG_ IndividualCellModTemp_Data_6 : 48|8@1+ (1,-100) [-100|155] "�C" Vector__XXX
 SG_ IndividualCellModTemp_Data_7 : 56|8@1+ (1,-100) [-100|155] "�C" Vector__XXX

BO_ 2578778112 Individual_Cell_Temp_Ext_A: 8 EMUS_BMS
 SG_ IndividualCellTemperature_Data_0 : 0|8@1+ (1,-100) [-100|155] "�C" Vector__XXX
 SG_ IndividualCellTemperature_Data_1 : 8|8@1+ (1,-100) [-100|155] "�C" Vector__XXX
 SG_ IndividualCellTemperature_Data_2 : 16|8@1+ (1,-100) [-100|155] "�C" Vector__XXX
 SG_ IndividualCellTemperature_Data_3 : 24|8@1+ (1,-100) [-100|155] "�C" Vector__XXX
 SG_ IndividualCellTemperature_Data_4 : 32|8@1+ (1,-100) [-100|155] "�C" Vector__XXX
 SG_ IndividualCellTemperature_Data_5 : 40|8@1+ (1,-100) [-100|155] "�C" Vector__XXX
 SG_ IndividualCellTemperature_Data_6 : 48|8@1+ (1,-100) [-100|155] "�C" Vector__XXX
 SG_ IndividualCellTemperature_Data_7 : 56|8@1+ (1,-100) [-100|155] "�C" Vector__XXX

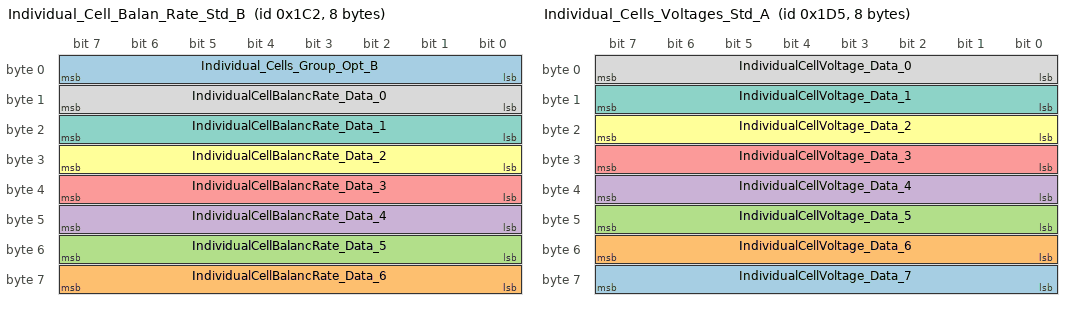
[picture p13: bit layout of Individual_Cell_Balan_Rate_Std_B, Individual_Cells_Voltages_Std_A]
BO_ 450 Individual_Cell_Balan_Rate_Std_B: 8 EMUS_BMS
 SG_ Individual_Cells_Group_Opt_B : 0|8@1+ (1,0) [0|255] "" Vector__XXX
 SG_ IndividualCellBalancRate_Data_6 : 56|8@1+ (0.392156862745098,0) [0|100] "%" Vector__XXX
 SG_ IndividualCellBalancRate_Data_5 : 48|8@1+ (0.392156862745098,0) [0|100] "%" Vector__XXX
 SG_ IndividualCellBalancRate_Data_4 : 40|8@1+ (0.392156862745098,0) [0|100] "%" Vector__XXX
 SG_ IndividualCellBalancRate_Data_3 : 32|8@1+ (0.392156862745098,0) [0|100] "%" Vector__XXX
 SG_ IndividualCellBalancRate_Data_2 : 24|8@1+ (0.392156862745098,0) [0|100] "%" Vector__XXX
 SG_ IndividualCellBalancRate_Data_1 : 16|8@1+ (0.392156862745098,0) [0|100] "%" Vector__XXX
 SG_ IndividualCellBalancRate_Data_0 : 8|8@1+ (0.392156862745098,0) [0|100] "%" Vector__XXX

BO_ 437 Overall_Parameters_Std: 8 EMUS_BMS
 SG_ OverallParams_NumberOfCells_LSB : 56|8@1+ (1,0) [0|255] "" Vector__XXX
 SG_ OverallParams_LastChargingError : 48|8@1+ (1,0) [0|255] "" Vector__XXX
 SG_ OverallParams_ChrgStageDurat_LSB : 40|8@1+ (1,0) [0|255] "" Vector__XXX
 SG_ OverallParams_ChrgStageDurat_MSB : 32|8@1+ (1,0) [0|255] "" Vector__XXX
 SG_ OverallParams_ChargingStage : 24|8@1+ (1,0) [0|255] "" Vector__XXX
 SG_ OverallParams_NumberOfCells_MSB : 16|8@1+ (1,0) [0|255] "" Vector__XXX
 SG_ OverallParams_ContactorPreCharge : 11|1@1+ (1,0) [0|1] "" Vector__XXX
 SG_ OverallParams_DCDC_Control : 10|1@1+ (1,0) [0|1] "" Vector__XXX
 SG_ OverallParams_ChargingInterlock : 9|1@1+ (1,0) [0|1] "" Vector__XXX
 SG_ OverallParams_PowerReduction : 8|1@1+ (1,0) [0|1] "" Vector__XXX
 SG_ OverallParams_BatteryFan : 7|1@1+ (1,0) [0|1] "" Vector__XXX
 SG_ OverallParams_BatteryContactor : 6|1@1+ (1,0) [0|1] "" Vector__XXX
 SG_ OverallParams_HeaterEnable : 5|1@1+ (1,0) [0|1] "" Vector__XXX
 SG_ OverallParams_ChargerEnable : 4|1@1+ (1,0) [0|1] "" Vector__XXX
 SG_ OverallParams_LeakageSensor : 3|1@1+ (1,0) [0|1] "" Vector__XXX
 SG_ OverallParams_FastCharge : 2|1@1+ (1,0) [0|1] "" Vector__XXX
 SG_ OverallParams_ChargerMains : 1|1@1+ (1,0) [0|1] "" Vector__XXX
 SG_ OverallParams_IgnitionKey : 0|1@1+ (1,0) [0|1] "" Vector__XXX

BO_ 444 Diagnostic_Codes_Std: 8 EMUS_BMS
 SG_ DiagnosticCodes_CellTempValid : 29|1@1+ (1,0) [0|1] "" Vector__XXX
 SG_ DiagnosticCodes_BatChrgFinished : 28|1@1+ (1,0) [0|1] "" Vector__XXX
 SG_ DiagnosticCodes_NumOfCellsValid : 27|1@1+ (1,0) [0|1] "" Vector__XXX
 SG_ DiagnosticCodes_CellBalancValid : 26|1@1+ (1,0) [0|1] "" Vector__XXX
 SG_ DiagnosticCodes_CellModTempValid : 25|1@1+ (1,0) [0|1] "" Vector__XXX
 SG_ DiagnosticCodes_CellVoltValidity : 24|1@1+ (1,0) [0|1] "" Vector__XXX
 SG_ DiagnosticCodes_PackUnderVoltage : 21|1@1+ (1,0) [0|1] "" Vector__XXX
 SG_ DiagnosticCodes_NoCurrentSensor : 20|1@1+ (1,0) [0|1] "" Vector__XXX
 SG_ DiagnosticCodes_CellOverHeat : 19|1@1+ (1,0) [0|1] "" Vector__XXX
 SG_ DiagnosticCodes_ACPresnce : 18|1@1+ (1,0) [0|1] "" Vector__XXX
 SG_ DiagnosticCodes_MSCommCANFail : 17|1@1+ (1,0) [0|1] "" Vector__XXX
 SG_ DiagnosticCodes_MSIntCANError : 16|1@1+ (1,0) [0|1] "" Vector__XXX
 SG_ DiagnosticCodes_HighCellTemp : 13|1@1+ (1,0) [0|1] "" Vector__XXX
 SG_ DiagnosticCodes_MSComMalfunc : 12|1@1+ (1,0) [0|1] "" Vector__XXX
 SG_ DiagnosticCodes_MSConfigMismatch : 11|1@1+ (1,0) [0|1] "" Vector__XXX
 SG_ DiagnosticCodes_HighCellModTemp : 10|1@1+ (1,0) [0|1] "" Vector__XXX
 SG_ DiagnosticCodes_HighCurrent : 9|1@1+ (1,0) [0|1] "" Vector__XXX
 SG_ DiagnosticCodes_LowVoltage : 8|1@1+ (1,0) [0|1] "" Vector__XXX
 SG_ DiagnosticCodes_MS_ConfError : 7|1@1+ (1,0) [0|1] "" Vector__XXX
 SG_ DiagnosticCodes_NoCellComm : 6|1@1+ (1,0) [0|1] "" Vector__XXX
 SG_ DiagnosticCodes_Leakage : 5|1@1+ (1,0) [0|1] "" Vector__XXX
 SG_ DiagnosticCodes_CellModOverHeat : 4|1@1+ (1,0) [0|1] "" Vector__XXX
 SG_ DiagnosticCodes_ChrgOverCurrent : 3|1@1+ (1,0) [0|1] "" Vector__XXX
 SG_ DiagnosticCodes_DchrgOvrCurrent : 2|1@1+ (1,0) [0|1] "" Vector__XXX
 SG_ DiagnosticCodes_OverVoltage : 1|1@1+ (1,0) [0|1] "" Vector__XXX
 SG_ DiagnosticCodes_UnderVoltage : 0|1@1+ (1,0) [0|1] "" Vector__XXX

BO_ 438 Battery_Volt_Overall_Param_Std: 8 EMUS_BMS
 SG_ VoltOverallParams_TotalVolt : 31|32@0+ (0.01,0) [0|42949672.95] "V" Vector__XXX
 SG_ VoltOverallParam_AvrgCellVoltage : 16|8@1+ (0.01,2) [2|4.55] "V" Vector__XXX
 SG_ VoltOverallParam_MaxCellVoltage : 8|8@1+ (0.01,2) [2|4.55] "V" Vector__XXX
 SG_ VoltOverallParam_MinCellVoltage : 0|8@1+ (0.01,2) [2|4.55] "V" Vector__XXX

BO_ 439 Cell_Mod_Temp_Overall_Param_Std: 8 EMUS_BMS
 SG_ CellModOverallPar_AvgCellModTemp : 16|8@1+ (1,-100) [-100|155] "�C" Vector__XXX
 SG_ CellModOverallPar_MaxCellModTemp : 8|8@1+ (1,-100) [-100|155] "�C" Vector__XXX
 SG_ CellModOverallPar_MinCellModTemp : 0|8@1+ (1,-100) [-100|155] "�C" Vector__XXX

BO_ 445 Cell_Temp_Overall_Param_Std: 8 EMUS_BMS
 SG_ CellOverallPar_MinCellTemp : 0|8@1+ (1,-100) [-100|155] "�C" Vector__XXX
 SG_ CellOverallPar_MaxCellTemp : 8|8@1+ (1,-100) [-100|155] "�C" Vector__XXX
 SG_ CellOverallPar_AvgCellTemp : 16|8@1+ (1,-100) [-100|155] "�C" Vector__XXX

BO_ 440 Cell_Balanc_Rate_Overall_Par_Std: 8 EMUS_BMS
 SG_ CellBalancPar_AvgCellBalancRate : 16|8@1+ (0.392156862745098,0) [0|100] "%" Vector__XXX
 SG_ CellBalancPar_MaxCellBalancRate : 8|8@1+ (0.392156862745098,0) [0|100] "%" Vector__XXX
 SG_ CellBalancPar_MinCellBalancRate : 0|8@1+ (0.392156862745098,0) [0|100] "%" Vector__XXX

BO_ 469 Individual_Cells_Voltages_Std_A: 8 EMUS_BMS
 SG_ IndividualCellVoltage_Data_7 : 56|8@1+ (0.01,2) [2|4.55] "V" Vector__XXX
 SG_ IndividualCellVoltage_Data_6 : 48|8@1+ (0.01,2) [2|4.55] "V" Vector__XXX
 SG_ IndividualCellVoltage_Data_5 : 40|8@1+ (0.01,2) [2|4.55] "V" Vector__XXX
 SG_ IndividualCellVoltage_Data_4 : 32|8@1+ (0.01,2) [2|4.55] "V" Vector__XXX
 SG_ IndividualCellVoltage_Data_3 : 24|8@1+ (0.01,2) [2|4.55] "V" Vector__XXX
 SG_ IndividualCellVoltage_Data_2 : 16|8@1+ (0.01,2) [2|4.55] "V" Vector__XXX
 SG_ IndividualCellVoltage_Data_1 : 8|8@1+ (0.01,2) [2|4.55] "V" Vector__XXX
 SG_ IndividualCellVoltage_Data_0 : 0|8@1+ (0.01,2) [2|4.55] "V" Vector__XXX

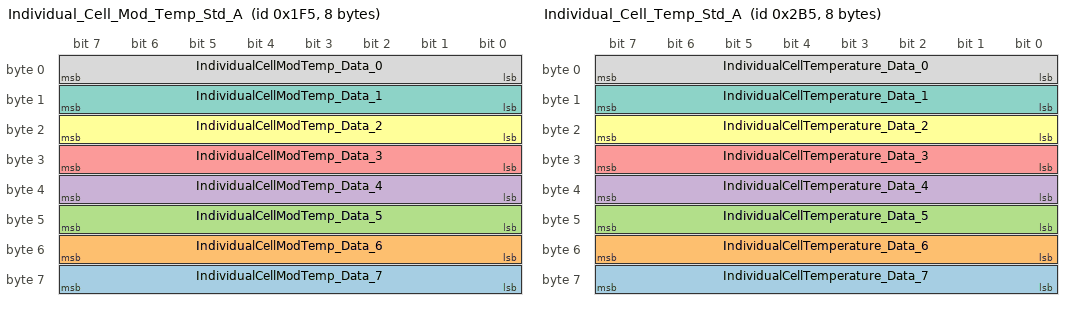
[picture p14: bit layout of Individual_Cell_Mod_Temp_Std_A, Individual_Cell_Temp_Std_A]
BO_ 501 Individual_Cell_Mod_Temp_Std_A: 8 EMUS_BMS
 SG_ IndividualCellModTemp_Data_7 : 56|8@1+ (1,-100) [-100|155] "�C" Vector__XXX
 SG_ IndividualCellModTemp_Data_6 : 48|8@1+ (1,-100) [-100|155] "�C" Vector__XXX
 SG_ IndividualCellModTemp_Data_5 : 40|8@1+ (1,-100) [-100|155] "�C" Vector__XXX
 SG_ IndividualCellModTemp_Data_4 : 32|8@1+ (1,-100) [-100|155] "�C" Vector__XXX
 SG_ IndividualCellModTemp_Data_3 : 24|8@1+ (1,-100) [-100|155] "�C" Vector__XXX
 SG_ IndividualCellModTemp_Data_2 : 16|8@1+ (1,-100) [-100|155] "�C" Vector__XXX
 SG_ IndividualCellModTemp_Data_1 : 8|8@1+ (1,-100) [-100|155] "�C" Vector__XXX
 SG_ IndividualCellModTemp_Data_0 : 0|8@1+ (1,-100) [-100|155] "�C" Vector__XXX

BO_ 565 Configuration_Parameters_Std: 8 EMUS_BMS
 SG_ ConfigParams_ParameterData : 39|32@0+ (1,0) [0|4294967295] "" Vector__XXX
 SG_ ConfigParams_ParameterSize : 16|8@1+ (1,0) [0|255] "" Vector__XXX
 SG_ ConfigParams_ParameterID : 7|16@0+ (1,0) [0|65535] "" Vector__XXX

BO_ 693 Individual_Cell_Temp_Std_A: 8 EMUS_BMS
 SG_ IndividualCellTemperature_Data_7 : 56|8@1+ (1,-100) [-100|155] "�C" Vector__XXX
 SG_ IndividualCellTemperature_Data_6 : 48|8@1+ (1,-100) [-100|155] "�C" Vector__XXX
 SG_ IndividualCellTemperature_Data_5 : 40|8@1+ (1,-100) [-100|155] "�C" Vector__XXX
 SG_ IndividualCellTemperature_Data_4 : 32|8@1+ (1,-100) [-100|155] "�C" Vector__XXX
 SG_ IndividualCellTemperature_Data_3 : 24|8@1+ (1,-100) [-100|155] "�C" Vector__XXX
 SG_ IndividualCellTemperature_Data_2 : 16|8@1+ (1,-100) [-100|155] "�C" Vector__XXX
 SG_ IndividualCellTemperature_Data_1 : 8|8@1+ (1,-100) [-100|155] "�C" Vector__XXX
 SG_ IndividualCellTemperature_Data_0 : 0|8@1+ (1,-100) [-100|155] "�C" Vector__XXX

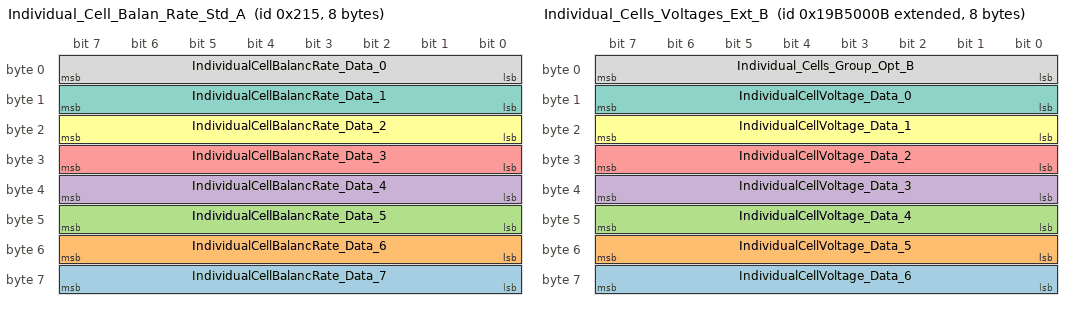
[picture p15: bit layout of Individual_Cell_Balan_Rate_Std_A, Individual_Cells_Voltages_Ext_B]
BO_ 533 Individual_Cell_Balan_Rate_Std_A: 8 EMUS_BMS
 SG_ IndividualCellBalancRate_Data_7 : 56|8@1+ (0.392156862745098,0) [0|100] "%" Vector__XXX
 SG_ IndividualCellBalancRate_Data_6 : 48|8@1+ (0.392156862745098,0) [0|100] "%" Vector__XXX
 SG_ IndividualCellBalancRate_Data_5 : 40|8@1+ (0.392156862745098,0) [0|100] "%" Vector__XXX
 SG_ IndividualCellBalancRate_Data_4 : 32|8@1+ (0.392156862745098,0) [0|100] "%" Vector__XXX
 SG_ IndividualCellBalancRate_Data_3 : 24|8@1+ (0.392156862745098,0) [0|100] "%" Vector__XXX
 SG_ IndividualCellBalancRate_Data_2 : 16|8@1+ (0.392156862745098,0) [0|100] "%" Vector__XXX
 SG_ IndividualCellBalancRate_Data_1 : 8|8@1+ (0.392156862745098,0) [0|100] "%" Vector__XXX
 SG_ IndividualCellBalancRate_Data_0 : 0|8@1+ (0.392156862745098,0) [0|100] "%" Vector__XXX

BO_ 566 Contactor_Control_Std: 1 ExternalDevice
 SG_ ContactorControl_ContactorState : 0|8@1+ (1,0) [0|255] "" Vector__XXX

BO_ 443 Energy_Parameters_Std: 8 EMUS_BMS
 SG_ Energy_DistanceTraveled : 55|16@0+ (0.1,0) [0|6553.5] "" Vector__XXX
 SG_ Energy_EstimatedDistanceLeft : 39|16@0+ (0.1,0) [0|6553.5] "" Vector__XXX
 SG_ Energy_EstimatedEnergy : 23|16@0+ (0.01,0) [0|655.35] "kWh" Vector__XXX
 SG_ Energy_EstimatedConsumption : 7|16@0+ (1,0) [0|65535] "Wh" Vector__XXX

BO_ 570 Events_Std: 8 EMUS_BMS
 SG_ Events_Data : 23|32@0+ (1,0) [0|4294967295] "" Vector__XXX
 SG_ Events_DataType : 8|8@1+ (1,0) [0|255] "" Vector__XXX
 SG_ Events_EntryNumber : 0|8@1+ (1,0) [0|255] "" Vector__XXX

BO_ 567 Login_Level_Std: 8 EMUS_BMS
 SG_ LoginLevel : 0|8@1+ (1,0) [0|255] "" Vector__XXX

BO_ 442 State_Of_Charge_Param_Std: 8 EMUS_BMS
 SG_ SOC_Params_EstimatedSOH : 40|8@1+ (1,0) [0|255] "" Vector__XXX
 SG_ SOCParams_EstimatedSOC : 32|8@1+ (1,0) [0|255] "" Vector__XXX
 SG_ SOCParams_EstimatedCharge : 23|16@0+ (1,0) [0|65535] "W/V" Vector__XXX
 SG_ SOCParams_Current : 7|16@0+ (0.1,0) [0|6553.5] "A" Vector__XXX

BO_ 569 Statistics_Std: 8 EMUS_BMS
 SG_ Statistics_Data : 23|32@0+ (1,0) [0|4294967295] "" Vector__XXX
 SG_ Statistics_DataType : 8|8@1+ (1,0) [0|255] "" Vector__XXX
 SG_ Statistics_Identifier : 0|8@1+ (1,0) [0|255] "" Vector__XXX

BO_ 2578776075 Individual_Cells_Voltages_Ext_B: 8 EMUS_BMS
 SG_ IndividualCellVoltage_Data_6 : 56|8@1+ (0.01,2) [2|4.55] "V" Vector__XXX
 SG_ IndividualCellVoltage_Data_5 : 48|8@1+ (0.01,2) [2|4.55] "V" Vector__XXX
 SG_ IndividualCellVoltage_Data_4 : 40|8@1+ (0.01,2) [2|4.55] "V" Vector__XXX
 SG_ IndividualCellVoltage_Data_3 : 32|8@1+ (0.01,2) [2|4.55] "V" Vector__XXX
 SG_ IndividualCellVoltage_Data_2 : 24|8@1+ (0.01,2) [2|4.55] "V" Vector__XXX
 SG_ IndividualCellVoltage_Data_1 : 16|8@1+ (0.01,2) [2|4.55] "V" Vector__XXX
 SG_ IndividualCellVoltage_Data_0 : 8|8@1+ (0.01,2) [2|4.55] "V" Vector__XXX
 SG_ Individual_Cells_Group_Opt_B : 0|8@1+ (1,0) [0|255] "" Vector__XXX

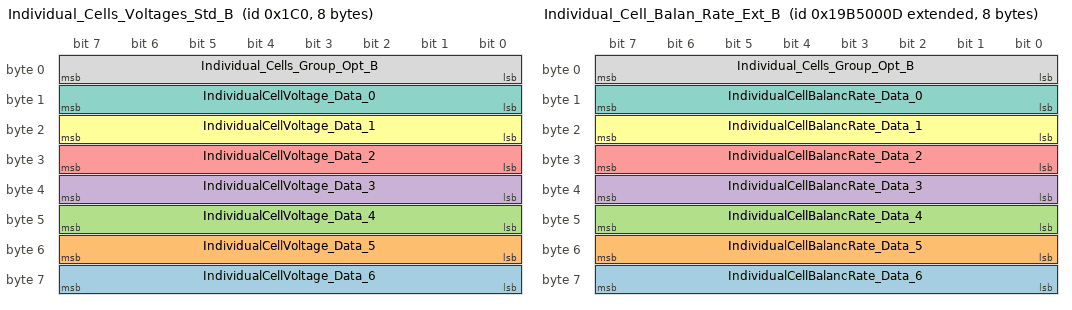
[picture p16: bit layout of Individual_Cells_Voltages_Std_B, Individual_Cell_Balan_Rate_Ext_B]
BO_ 448 Individual_Cells_Voltages_Std_B: 8 EMUS_BMS
 SG_ IndividualCellVoltage_Data_6 : 56|8@1+ (0.01,2) [2|4.55] "V" Vector__XXX
 SG_ IndividualCellVoltage_Data_5 : 48|8@1+ (0.01,2) [2|4.55] "V" Vector__XXX
 SG_ IndividualCellVoltage_Data_4 : 40|8@1+ (0.01,2) [2|4.55] "V" Vector__XXX
 SG_ IndividualCellVoltage_Data_3 : 32|8@1+ (0.01,2) [2|4.55] "V" Vector__XXX
 SG_ IndividualCellVoltage_Data_2 : 24|8@1+ (0.01,2) [2|4.55] "V" Vector__XXX
 SG_ IndividualCellVoltage_Data_1 : 16|8@1+ (0.01,2) [2|4.55] "V" Vector__XXX
 SG_ IndividualCellVoltage_Data_0 : 8|8@1+ (0.01,2) [2|4.55] "V" Vector__XXX
 SG_ Individual_Cells_Group_Opt_B : 0|8@1+ (1,0) [0|255] "" Vector__XXX

BO_ 2578776077 Individual_Cell_Balan_Rate_Ext_B: 8 EMUS_BMS
 SG_ IndividualCellBalancRate_Data_6 : 56|8@1+ (0.392156862745098,0) [0|100] "%" Vector__XXX
 SG_ IndividualCellBalancRate_Data_5 : 48|8@1+ (0.392156862745098,0) [0|100] "%" Vector__XXX
 SG_ IndividualCellBalancRate_Data_4 : 40|8@1+ (0.392156862745098,0) [0|100] "%" Vector__XXX
 SG_ IndividualCellBalancRate_Data_3 : 32|8@1+ (0.392156862745098,0) [0|100] "%" Vector__XXX
 SG_ IndividualCellBalancRate_Data_2 : 24|8@1+ (0.392156862745098,0) [0|100] "%" Vector__XXX
 SG_ IndividualCellBalancRate_Data_1 : 16|8@1+ (0.392156862745098,0) [0|100] "%" Vector__XXX
 SG_ IndividualCellBalancRate_Data_0 : 8|8@1+ (0.392156862745098,0) [0|100] "%" Vector__XXX
 SG_ Individual_Cells_Group_Opt_B : 0|8@1+ (1,0) [0|255] "" Vector__XXX

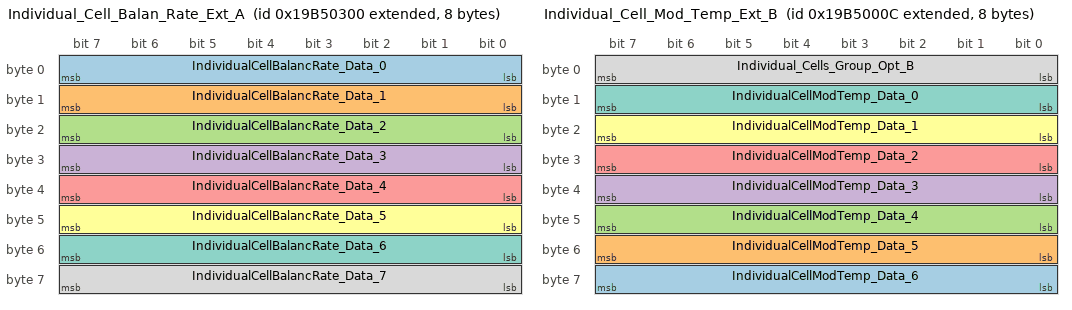
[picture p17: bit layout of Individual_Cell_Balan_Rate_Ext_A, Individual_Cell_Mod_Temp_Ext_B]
BO_ 2578776832 Individual_Cell_Balan_Rate_Ext_A: 8 EMUS_BMS
 SG_ IndividualCellBalancRate_Data_0 : 0|8@1+ (0.392156862745098,0) [0|100] "%" Vector__XXX
 SG_ IndividualCellBalancRate_Data_1 : 8|8@1+ (0.392156862745098,0) [0|100] "%" Vector__XXX
 SG_ IndividualCellBalancRate_Data_2 : 16|8@1+ (0.392156862745098,0) [0|100] "%" Vector__XXX
 SG_ IndividualCellBalancRate_Data_3 : 24|8@1+ (0.392156862745098,0) [0|100] "%" Vector__XXX
 SG_ IndividualCellBalancRate_Data_4 : 32|8@1+ (0.392156862745098,0) [0|100] "%" Vector__XXX
 SG_ IndividualCellBalancRate_Data_5 : 40|8@1+ (0.392156862745098,0) [0|100] "%" Vector__XXX
 SG_ IndividualCellBalancRate_Data_6 : 48|8@1+ (0.392156862745098,0) [0|100] "%" Vector__XXX
 SG_ IndividualCellBalancRate_Data_7 : 56|8@1+ (0.392156862745098,0) [0|100] "%" Vector__XXX

BO_ 2578776076 Individual_Cell_Mod_Temp_Ext_B: 8 EMUS_BMS
 SG_ IndividualCellModTemp_Data_6 : 56|8@1+ (1,-100) [-100|155] "�C" Vector__XXX
 SG_ IndividualCellModTemp_Data_5 : 48|8@1+ (1,-100) [-100|155] "�C" Vector__XXX
 SG_ IndividualCellModTemp_Data_4 : 40|8@1+ (1,-100) [-100|155] "�C" Vector__XXX
 SG_ IndividualCellModTemp_Data_3 : 32|8@1+ (1,-100) [-100|155] "�C" Vector__XXX
 SG_ IndividualCellModTemp_Data_2 : 24|8@1+ (1,-100) [-100|155] "�C" Vector__XXX
 SG_ IndividualCellModTemp_Data_1 : 16|8@1+ (1,-100) [-100|155] "�C" Vector__XXX
 SG_ IndividualCellModTemp_Data_0 : 8|8@1+ (1,-100) [-100|155] "�C" Vector__XXX
 SG_ Individual_Cells_Group_Opt_B : 0|8@1+ (1,0) [0|255] "" Vector__XXX

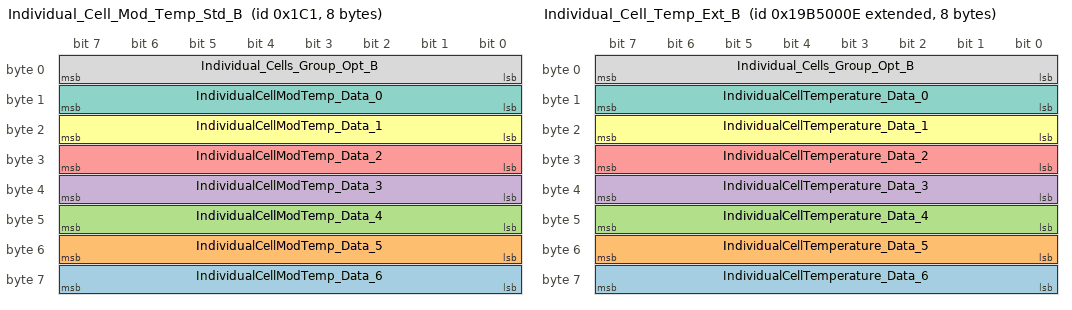
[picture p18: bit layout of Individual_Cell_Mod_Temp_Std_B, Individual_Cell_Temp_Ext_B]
BO_ 449 Individual_Cell_Mod_Temp_Std_B: 8 EMUS_BMS
 SG_ IndividualCellModTemp_Data_6 : 56|8@1+ (1,-100) [-100|155] "�C" Vector__XXX
 SG_ IndividualCellModTemp_Data_5 : 48|8@1+ (1,-100) [-100|155] "�C" Vector__XXX
 SG_ IndividualCellModTemp_Data_4 : 40|8@1+ (1,-100) [-100|155] "�C" Vector__XXX
 SG_ IndividualCellModTemp_Data_3 : 32|8@1+ (1,-100) [-100|155] "�C" Vector__XXX
 SG_ IndividualCellModTemp_Data_2 : 24|8@1+ (1,-100) [-100|155] "�C" Vector__XXX
 SG_ IndividualCellModTemp_Data_1 : 16|8@1+ (1,-100) [-100|155] "�C" Vector__XXX
 SG_ IndividualCellModTemp_Data_0 : 8|8@1+ (1,-100) [-100|155] "�C" Vector__XXX
 SG_ Individual_Cells_Group_Opt_B : 0|8@1+ (1,0) [0|255] "" Vector__XXX

BO_ 2578776078 Individual_Cell_Temp_Ext_B: 8 EMUS_BMS
 SG_ IndividualCellTemperature_Data_6 : 56|8@1+ (1,-100) [-100|155] "�C" Vector__XXX
 SG_ IndividualCellTemperature_Data_5 : 48|8@1+ (1,-100) [-100|155] "�C" Vector__XXX
 SG_ IndividualCellTemperature_Data_4 : 40|8@1+ (1,-100) [-100|155] "�C" Vector__XXX
 SG_ IndividualCellTemperature_Data_3 : 32|8@1+ (1,-100) [-100|155] "�C" Vector__XXX
 SG_ IndividualCellTemperature_Data_2 : 24|8@1+ (1,-100) [-100|155] "�C" Vector__XXX
 SG_ IndividualCellTemperature_Data_1 : 16|8@1+ (1,-100) [-100|155] "�C" Vector__XXX
 SG_ IndividualCellTemperature_Data_0 : 8|8@1+ (1,-100) [-100|155] "�C" Vector__XXX
 SG_ Individual_Cells_Group_Opt_B : 0|8@1+ (1,0) [0|255] "" Vector__XXX

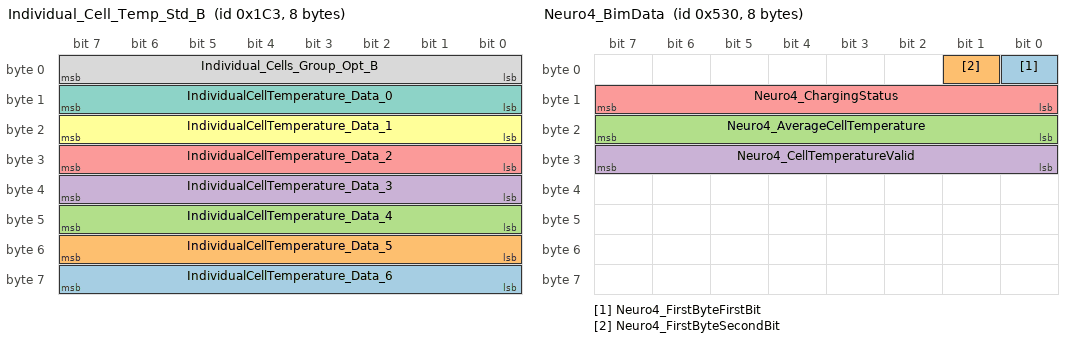
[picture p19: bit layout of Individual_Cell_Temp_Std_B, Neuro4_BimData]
BO_ 451 Individual_Cell_Temp_Std_B: 8 EMUS_BMS
 SG_ IndividualCellTemperature_Data_6 : 56|8@1+ (1,-100) [-100|155] "�C" Vector__XXX
 SG_ IndividualCellTemperature_Data_5 : 48|8@1+ (1,-100) [-100|155] "�C" Vector__XXX
 SG_ IndividualCellTemperature_Data_4 : 40|8@1+ (1,-100) [-100|155] "�C" Vector__XXX
 SG_ IndividualCellTemperature_Data_3 : 32|8@1+ (1,-100) [-100|155] "�C" Vector__XXX
 SG_ IndividualCellTemperature_Data_2 : 24|8@1+ (1,-100) [-100|155] "�C" Vector__XXX
 SG_ IndividualCellTemperature_Data_1 : 16|8@1+ (1,-100) [-100|155] "�C" Vector__XXX
 SG_ IndividualCellTemperature_Data_0 : 8|8@1+ (1,-100) [-100|155] "�C" Vector__XXX
 SG_ Individual_Cells_Group_Opt_B : 0|8@1+ (1,0) [0|255] "" Vector__XXX

BO_ 2578777091 Login_Set_Password_Status_Ext: 8 ExternalDevice
 SG_ LoginSetPasswordStatus : 0|8@1+ (1,0) [0|255] "" Vector__XXX

BO_ 1313 Neuro1_Battery_Data: 8 EMUS_BMS
 SG_ Neuro1_DepthOfDischarge : 0|16@1+ (0.1,0) [0|1000] "%" Vector__XXX

BO_ 1314 Neuro2_Battery_Data: 8 EMUS_BMS
 SG_ Neuro2_BatteryVoltMinDischrg : 32|16@1+ (0.1,0) [0|6553.5] "V" Vector__XXX
 SG_ Neuro2_Dischrg_Current_Warn : 48|16@1+ (0.1,0) [0|6553.5] "A" Vector__XXX

BO_ 1315 Neuro3_Battery_Data: 8 EMUS_BMS
 SG_ Neuro3_BatVoltMaxRegen : 0|16@1+ (0.1,0) [0|6553.5] "V" Vector__XXX
 SG_ Neuro3_ChrgCurrentLimit : 16|16@1+ (0.1,0) [0|6553.5] "A" Vector__XXX

BO_ 1328 Neuro4_BimData: 8 EMUS_BMS
 SG_ Neuro4_FirstByteFirstBit : 0|1@1+ (1,0) [0|1] "" Vector__XXX
 SG_ Neuro4_FirstByteSecondBit : 1|1@1+ (1,0) [0|1] "" Vector__XXX
 SG_ Neuro4_AverageCellTemperature : 16|8@1+ (1,40) [0|255] "�C" Vector__XXX
 SG_ Neuro4_CellTemperatureValid : 24|8@1+ (1,0) [0|255] "" Vector__XXX
 SG_ Neuro4_ChargingStatus : 8|8@1+ (1,0) [0|255] "" Vector__XXX

BO_ 572 ChargingStation_Std: 8 ExternalDevice
 SG_ ChargingStation_DCCurrentLim : 7|16@0+ (0.1,0) [0|6553.5] "A" Vector__XXX
 SG_ ChargingStation_ACCurrentLim : 23|16@0+ (0.1,0) [0|6553.5] "A" Vector__XXX
 SG_ ChargingStation_ACVoltage : 39|16@0+ (0.1,0) [0|6553.5] "V" Vector__XXX
 SG_ ChargingStation_PowerLimit : 55|16@0+ (1,0) [0|65535] "W" Vector__XXX

BO_ 2578777095 ChargingStation_Ext: 8 ExternalDevice
 SG_ ChargingStation_PowerLimit : 55|16@0+ (1,0) [0|65535] "W" Vector__XXX
 SG_ ChargingStation_ACVoltage : 39|16@0+ (0.1,0) [0|6553.5] "V" Vector__XXX
 SG_ ChargingStation_ACCurrentLim : 23|16@0+ (0.1,0) [0|6553.5] "A" Vector__XXX
 SG_ ChargingStation_DCCurrentLim : 7|16@0+ (0.1,0) [0|6553.5] "A" Vector__XXX

BO_TX_BU_ 2578777088 : ExternalDevice,EMUS_BMS;
BO_TX_BU_ 565 : ExternalDevice,EMUS_BMS;

SIG_VALTYPE_ 2148139008 GPS_Latitude : 1;
SIG_VALTYPE_ 2148139008 GPS_Longitude : 1;

BA_DEF_ SG_  "SPN" INT 0 524287;
BA_DEF_ BO_  "VFrameFormat" ENUM  "StandardCAN","ExtendedCAN","reserved","J1939PG";
BA_DEF_  "DatabaseVersion" STRING ;
BA_DEF_  "BusType" STRING ;
BA_DEF_  "ProtocolType" STRING ;
BA_DEF_  "DatabaseCompiler" STRING ;
BA_DEF_DEF_  "SPN" 0;
BA_DEF_DEF_  "VFrameFormat" "J1939PG";
BA_DEF_DEF_  "DatabaseVersion" "DEMO PLUS";
BA_DEF_DEF_  "BusType" "";
BA_DEF_DEF_  "ProtocolType" "";
BA_DEF_DEF_  "DatabaseCompiler" "";
BA_ "ProtocolType" "J1939";
BA_ "DatabaseCompiler" "CSS ELECTRONICS (WWW.CSSELECTRONICS.COM)";
BA_ "DatabaseVersion" "1.0.0";
BA_ "SPN" SG_ 2364540158 EngineSpeed 190;

CM_ BU_ INV "The Cascadia Motion inverter";
CM_ BU_ U2C "Delphi DC/DC Converter";
CM_ BU_ VCU "The system vehicle control unit";
CM_ BU_ BMS "BMS Master";
CM_ SG_ 173 D4_Iq_Command "The commanded Q-axis current";
CM_ SG_ 173 D3_Id_Command "The commanded D-axis current";
CM_ SG_ 173 D2_Flux_Weakening_Output "This is the current output of the flux regulator.";
CM_ SG_ 173 D1_Modulation_Index "This is the modulation index. The scale factor is x100. To get the actual modulation index divide the value by 100.";
CM_ SG_ 172 D3_Power_On_Timer "Updated every 3 msec. This will roll over in approximately 150 days!";
CM_ SG_ 172 D2_Torque_Feedback "Estimated motor torque feedback";
CM_ SG_ 172 D1_Commanded_Torque "The commanded Torque";
CM_ BO_ 194 "The inverter response to each Parameter message that is received.";
CM_ SG_ 194 D2_Write_Success "0=Write failure, 1=Success";
CM_ SG_ 194 D3_Data_Response "All EEPROM data is 16 bits and is contained in bytes 4 and 5. Bytes 6 and 7 should be ignored.";
CM_ SG_ 194 D1_Parameter_Address_Response "Valid EEPROM Parameter CAN addresses are between 100 and 499.";
CM_ BO_ 193 "Parameter Message sent as needed by VCU to request info, change EEPROM, or command a function.";
CM_ SG_ 193 D3_Data_Command "All EEPROM data is 16 bits and is contained in bytes 4 and 5.";
CM_ SG_ 193 D2_Read_Write_Command "0=Read, 1=Write";
CM_ SG_ 193 D1_Parameter_Address_Command "Valid EEPROM Parameter CAN addresses are between 100 and 499.";
CM_ BO_ 192 "The command message is used to transmit data to the controller. This message is sent from a user supplied external controller to the PMxxx controller.";
CM_ SG_ 192 Inverter_Enable "0=Inverter OFF, 1 = Inverter ON";
CM_ SG_ 192 Direction_Command "0=CW, 1=CCW as veiwed from the shaft end of the motor";
CM_ SG_ 192 Speed_Command "Speed commandused when in speed mode";
CM_ SG_ 192 Torque_Command "Torque command when in torque mode";
CM_ SG_ 192 Inverter_Discharge "0=Discharge Disable,
=Discharge Enable";
CM_ SG_ 192 Torque_Limit_Command "Torque Limit, set to 0 to keep default";
CM_ SG_ 192 Speed_Mode_Enable "0 = No change to mode, 1 = change to speed mode from torque mode";
CM_ SG_ 192 RollingCounter "Rolling Counter command";
CM_ SG_ 171 D4_Run_Fault_Hi "Each bit represents a fault. Please refer to PM100 Users Manual for details.";
CM_ SG_ 171 D2_Post_Fault_Hi "Each bit represents a fault. Please refer to PM100 Users Manual for details.";
CM_ SG_ 171 D3_Run_Fault_Lo "Each bit represents a fault. Please refer to PM100 Users Manual for details.";
CM_ SG_ 171 D1_Post_Fault_Lo "Each bit represents a fault. Please refer to PM100 Users Manual for details.";
CM_ SG_ 170 D7_Direction_Command "1 = Forward
0 = 'Reverse' if inverter enabled  & 'Stopped' if inverter is disabled";
CM_ SG_ 170 D6_Inverter_Enable_State "0=Inverter Disabled, 
1=Inverter Enabled";
CM_ SG_ 170 D3_Relay_3_Status "0=OFF, 1=ON";
CM_ SG_ 170 D3_Relay_4_Status "0=OFF, 1=ON";
CM_ SG_ 170 D3_Relay_2_Status "0=OFF, 1=ON";
CM_ SG_ 170 D4_Inverter_Run_Mode "0=Torque Mode, 1=Speed Mode";
CM_ SG_ 170 D5_Inverter_Command_Mode "0=CAN mode, 1=VSM mode";
CM_ SG_ 170 D3_Relay_1_Status "0=OFF, 1=ON";
CM_ SG_ 170 D2_Inverter_State "Different states for the inverter state machine";
CM_ SG_ 170 D1_VSM_State "Different states for the vehicle state machine";
CM_ SG_ 170 D6_Inverter_Enable_Lockout "0=Lockout Disabled, 1=Lockout Enabled";
CM_ SG_ 170 D4_Inverter_Discharge_State "0 = Disabled, 1 = Enabled, 2 = Speed Check, 3 = Active, 4 = Complete";
CM_ SG_ 170 D3_Relay_5_Status "0=OFF, 1=ON";
CM_ SG_ 170 D3_Relay_6_Status "0=OFF, 1=ON";
CM_ SG_ 170 D7_BMS_Active "0 = BMS Not Active, 1 = BMS Active";
CM_ SG_ 170 D7_BMS_Torque_Limiting "0 = Not Limiting, 1 = Limiting";
CM_ SG_ 170 D7_Max_Speed_Limiting "0 = Not Limiting, 1 = torque limiting due to maximum speed";
CM_ SG_ 170 D7_Low_Speed_Limiting "0 = Not Limiting, 1 = Current limiting due to low motor speed";
CM_ SG_ 170 D5_Rolling_Counter "The current rolling counter value.";
CM_ SG_ 170 D1_PWM_Frequency "The inverter PWM frequency";
CM_ SG_ 170 D6_Start_Mode_Active "If in Key Switch Mode 1 then indicates status of Start input being applied.  0 = not active, 1 = active";
CM_ SG_ 169 D4_Reference_Voltage_12_0 "12V Input Voltage";
CM_ SG_ 169 D3_Reference_Voltage_5_0 "Transducer voltage";
CM_ SG_ 169 D2_Reference_Voltage_2_5 "Internal reference voltage";
CM_ SG_ 169 D1_Reference_Voltage_1_5 "Internal reference voltage";
CM_ SG_ 168 D4_Iq "The measured Iq current";
CM_ SG_ 168 D3_Id "The measured Id current";
CM_ SG_ 168 D2_Flux_Feedback "The estimated flux";
CM_ SG_ 168 D1_Flux_Command "The commanded flux";
CM_ SG_ 167 D4_VBC_Vq_Voltage "Measured value of the voltage between Phase B and Phase C";
CM_ SG_ 167 D3_VAB_Vd_Voltage "Measured value of the voltage betwen phase A and Phase B";
CM_ SG_ 167 D2_Output_Voltage "The calculated value of the output voltage, in peak line-neutral volts";
CM_ SG_ 167 D1_DC_Bus_Voltage "The actual measured value of the DC bus voltage";
CM_ SG_ 166 D4_DC_Bus_Current "The Calculated DC Bus Current";
CM_ SG_ 166 D3_Phase_C_Current "The measured value of Phase C current";
CM_ SG_ 166 D2_Phase_B_Current "The measured value of Phase B current";
CM_ SG_ 166 D1_Phase_A_Current "The measured value of Phase A current";
CM_ SG_ 165 D4_Delta_Resolver_Filtered "Used in calibration of resolver angle adjustment.";
CM_ SG_ 165 D3_Electrical_Output_Frequency "The actual electrical frequency of the inverter";
CM_ SG_ 165 D2_Motor_Speed "The measured speed of the motor";
CM_ SG_ 165 D1_Motor_Angle_Electrical "The Electrical Angle of the motor as read by the encoder or resolver";
CM_ SG_ 164 D5_Digital_Input_5 "Status of Digital Input #5";
CM_ SG_ 164 D4_Digital_Input_4 "Status of Digital Input #4";
CM_ SG_ 164 D3_Digital_Input_3 "Status of Digital Input #3";
CM_ SG_ 164 D2_Digital_Input_2 "Status of Digital Input #2";
CM_ SG_ 164 D1_Digital_Input_1 "Status of Digital Input #1";
CM_ SG_ 164 D6_Digital_Input_6 "Status of Digital Input #6";
CM_ SG_ 164 D7_Digital_Input_7 "Status of Digital Input #7";
CM_ SG_ 164 D8_Digital_Input_8 "Status of Digital Input #8";
CM_ SG_ 163 D4_Analog_Input_4 "Voltage on Analog Input #4";
CM_ SG_ 163 D3_Analog_Input_3 "Voltage on Analog Input #3";
CM_ SG_ 163 D2_Analog_Input_2 "Voltage on Analog Input #2";
CM_ SG_ 163 D1_Analog_Input_1 "Voltage on Analog Input #1";
CM_ SG_ 163 D5_Analog_Input_5 "Voltage on Analog Input #5";
CM_ SG_ 163 D6_Analog_Input_6 "Voltage on Analog Input #6";
CM_ SG_ 162 D4_Torque_Shudder "Shudder compensation value of torque";
CM_ SG_ 162 D3_Motor_Temperature "Motor Temperature Sensor";
CM_ SG_ 162 D2_RTD5_Temperature "RTD 5 (PT1000) Temperature (Gen 2 only)";
CM_ SG_ 162 D1_RTD4_Temperature "RTD 4 (PT1000) Temperature (Gen 2 only)";
CM_ SG_ 161 D4_RTD3_Temperature "RTD input 3 (PT1000) Temperature (Gen 2 only)";
CM_ SG_ 161 D3_RTD2_Temperature "RTD input 2 (PT1000) Temperature";
CM_ SG_ 161 D2_RTD1_Temperature "RTD input 1 (PT1000) Temperature";
CM_ SG_ 161 D1_Control_Board_Temperature "Control Board Temperature";
CM_ SG_ 160 D4_Gate_Driver_Board "Gate Driver Board Temperature";
CM_ SG_ 160 D3_Module_C "IGBT Module C Temperature";
CM_ SG_ 160 D2_Module_B "IGBT Module B Temperature";
CM_ SG_ 160 D1_Module_A "IGBT Module A Temperature";
CM_ BO_ 471 "Enable message sent to Delphi DC/DC converter.";
CM_ BO_ 469 "Response from Delphi DC/DC converter.";
CM_ BO_ 514 "Message sent by BMS for inverter DC current limiting.";
CM_ SG_ 514 D1_Max_Discharge_Current "Maximum discharge current from BMS";
CM_ SG_ 514 D2_Max_Charge_Current "Maximum charge current from BMS";
CM_ BO_ 176 "To enable fast message set CAN ACTIVE MSGS HI WORD to 0xFFFE.  Setting to default value of 0xFFFF will disable the fast message.";
CM_ SG_ 176 Fast_Torque_Command "The commanded torque";
CM_ SG_ 176 Fast_Torque_Feedback "The estimated torque";
CM_ SG_ 176 Fast_Motor_Speed "Motor speed";
CM_ SG_ 176 Fast_DC_Bus_Voltage "DC Bus Voltage";
BA_DEF_ BO_  "GenMsgCycleTime" INT 0 100000;
BA_DEF_  "BusType" STRING ;
BA_DEF_DEF_  "GenMsgCycleTime" 0;
BA_DEF_DEF_  "BusType" "CAN";
BA_ "GenMsgCycleTime" BO_ 172 10;
BA_ "GenMsgCycleTime" BO_ 192 5;
BA_ "GenMsgCycleTime" BO_ 171 100;
BA_ "GenMsgCycleTime" BO_ 170 100;
BA_ "GenMsgCycleTime" BO_ 169 100;
BA_ "GenMsgCycleTime" BO_ 168 10;
BA_ "GenMsgCycleTime" BO_ 167 10;
BA_ "GenMsgCycleTime" BO_ 166 10;
BA_ "GenMsgCycleTime" BO_ 165 10;
BA_ "GenMsgCycleTime" BO_ 164 10;
BA_ "GenMsgCycleTime" BO_ 163 10;
BA_ "GenMsgCycleTime" BO_ 162 100;
BA_ "GenMsgCycleTime" BO_ 161 100;
BA_ "GenMsgCycleTime" BO_ 160 100;
BA_ "GenMsgCycleTime" BO_ 176 3;
VAL_ 192 Inverter_Enable 0 "Turn the inverter OFF" 1 "Turn the Inverter ON" ;
VAL_ 192 Direction_Command 0 "CW" 1 "CCW" ;
VAL_ 192 Inverter_Discharge 0 "Discharge Disable" 1 "Discharge Enable (if EEPROM parameter is set)" ;
VAL_ 170 D2_Inverter_State 0 "Power up" 1 "Stop" 2 "Open Loop" 3 "Closed Loop" 4 "Internal State" 5 "Internal State" 6 "Internal State" 7 "Internal State" 8 "Idle Run" 9 "Idle Stop" 10 "Internal State" 11 "Intern State" 12 "Internal State" ;
VAL_ 170 D1_VSM_State 0 "VSM Start State" 1 "Pre-Charge Init state" 2 "pre-charge active state" 3 "pre-charge complete state" 4 "VSM wait state" 5 "VSM ready state" 6 "Motor Running State" 7 "blink fault code state" 14 "Shutdown state for Key Switch Mode 1" 15 "Reset the inverter" ;

CM_ BO_ 2578776070 "Energy Parameters Extended";
CM_ BO_ 2578776069 "State Of Charge Parameters Extended";
CM_ BO_ 2578776065 "Battery Voltage Overall Parameters Extended";
CM_ BO_ 2578776064 "Overall Parameters Extended";
CM_ BO_ 2578776071 "Diagnostic Codes Extended";
CM_ SG_ 2578776071 DiagnosticCodes_MSComMalfunc "DiagnosticCodes Master Slave Communication Malfunction";
CM_ BO_ 2578776066 "Cell Module Temperature Overall Parameters Extended";
CM_ BO_ 2578776072 "Cell Temperature Overall Parameters Extended";
CM_ BO_ 2578776067 "Cell Balancing Overall Parameters Extended";
CM_ BO_ 2578777088 "Configuration Parameters Extended";
CM_ BO_ 2578777090 "Login Request Response Extended";
CM_ BO_ 2578777089 "Contactor Control Extended";
CM_ BO_ 2578777600 "Energy Parameters Extended";
CM_ BO_ 2578777344 "State Of Charge Parameters Extended";
CM_ BO_ 2578777092 "Statistics Extended";
CM_ BO_ 2578777093 "Events Extended";
CM_ BO_ 2578776320 "Individual Cells Voltages Extended Option A";
CM_ BO_ 2578776576 "Individual Cell Module Temperatures Extended Option A";
CM_ BO_ 2578778112 "Individual Cell Temperatures Extended Option A";
CM_ BO_ 450 "Individual Cell Balancing Rates Standard Option B";
CM_ SG_ 450 Individual_Cells_Group_Opt_B "Individual Cells Group Value for CAN Option B";
CM_ BO_ 437 "Overall Parameters Standard";
CM_ BO_ 444 "Diagnostic Codes Standard";
CM_ SG_ 444 DiagnosticCodes_MSComMalfunc "DiagnosticCodes Master Slave Communication Malfunction";
CM_ BO_ 438 "Battery Voltage Overall Parameters Standard";
CM_ BO_ 439 "Cell Module Overall Parameters Standard";
CM_ BO_ 445 "Cell Temperature Overall Params Standard";
CM_ BO_ 440 "Cell Bancing Rate Overall Params Standard";
CM_ BO_ 469 "Individual Cells Voltages Standard Option A";
CM_ BO_ 501 "Individual Cell Module Temperature Standard Option A";
CM_ BO_ 693 "Individual Cell Temperatures Standard Option A";
CM_ BO_ 533 "Individual Cell Balancing Rates Standard Option A";
CM_ BO_ 566 "Contactor Control Standard";
CM_ BO_ 443 "Energy Parameters Standard";
CM_ BO_ 442 "State Of Charge Parameters Standard";
CM_ BO_ 569 "Statistics Standard";
CM_ BO_ 2578776075 "Individual Cells Voltages Extended Option B";
CM_ SG_ 2578776075 Individual_Cells_Group_Opt_B "Individual Cells Group Value for CAN Option B";
CM_ BO_ 448 "Individual Cells Voltages Standard Option B";
CM_ SG_ 448 Individual_Cells_Group_Opt_B "Individual Cells Group Value for CAN Option B";
CM_ BO_ 2578776077 "Individual Cell Balancing Rate Extended Option B";
CM_ SG_ 2578776077 Individual_Cells_Group_Opt_B "Individual Cells Group Value for CAN Option B";
CM_ BO_ 2578776832 "Individual Cell Balancing Rate Extended Option A";
CM_ BO_ 2578776076 "Individual Cell Modules Temperature Extended Option B";
CM_ SG_ 2578776076 Individual_Cells_Group_Opt_B "Individual Cells Group Value for CAN Option B";
CM_ BO_ 449 "Individual Cell Module Temperature Standard Option B";
CM_ SG_ 449 Individual_Cells_Group_Opt_B "Individual Cells Group Value for CAN Option B";
CM_ BO_ 2578776078 "Individual Cell Temperatures Extended Option B";
CM_ SG_ 2578776078 Individual_Cells_Group_Opt_B "Individual Cells Group Value for CAN Option B";
CM_ BO_ 451 "Individual Cell Temperature Standard Option B";
CM_ SG_ 451 Individual_Cells_Group_Opt_B "Individual Cells Group Value for CAN Option B";
CM_ SG_ 1328 Neuro4_FirstByteFirstBit "Contactor State";
CM_ SG_ 1328 Neuro4_FirstByteSecondBit "if max cell voltage is less than fully charge minus balancing range, then allow regeneration";
BA_DEF_  "BusType" STRING ;
BA_DEF_DEF_  "BusType" "CAN";
VAL_ 2578776064 OverallParams_IgnitionKey 0 "OFF" 1 "ON" ;
VAL_ 2578776064 OverallParams_ChargerMains 0 "OFF" 1 "ON" ;
VAL_ 2578776064 OverallParams_FastCharge 0 "OFF" 1 "ON" ;
VAL_ 2578776064 OverallParams_LeakageSensor 0 "OFF" 1 "ON" ;
VAL_ 2578776064 OverallParams_ChargerEnable 0 "OFF" 1 "ON" ;
VAL_ 2578776064 OverallParams_HeaterEnable 0 "OFF" 1 "ON" ;
VAL_ 2578776064 OverallParams_BatteryContactor 0 "OFF" 1 "ON" ;
VAL_ 2578776064 OverallParams_BatteryFan 0 "OFF" 1 "ON" ;
VAL_ 2578776064 OverallParams_PowerReduction 0 "OFF" 1 "ON" ;
VAL_ 2578776064 OverallParams_DCDC_Control 0 "OFF" 1 "ON" ;
VAL_ 2578776064 OverallParams_ContactorPreCharge 0 "OFF" 1 "ON" ;
VAL_ 2578776064 OverallParams_ChargingStage 0 "OFF" 1 "ON" ;
VAL_ 2578776064 OverallParams_LastChargingError 0 "No Error" 1 "No Cell Communication" 2 "No Cell Communication 2" 3 "Maximum Charging Stage Duration Expired" 4 "Cell Communication Lost" 5 "Cannot Set Cell Module Balancing Threshold" 6 "Cell or Cell Module Temperature To High" 7 "Cell Commucation Lost 2" 8 "Number Of Cells Mismatch" 9 "Cell Over Voltage" 10 "Cell Protection Event Occurred" ;
VAL_ 2578776064 OverallParams_ChargingInterlock 0 "OFF" 1 "ON" ;
VAL_ 2578776064 OverallParams_ChrgStageDurat_LSB 0 "No Error" 1 "No Cell Communication" 2 "No Cell Communication 2" 3 "Maximum Charging Stage Duration Expired" 4 "Cell Communication Lost" 5 "Cannot Set Cell Module Balancing Threshold" 6 "Cell or Cell Module Temperature To High" 7 "Cell Commucation Lost 2" 8 "Number Of Cells Mismatch" 9 "Cell Over Voltage" 10 "Cell Protection Event Occurred" ;
VAL_ 2578777090 LoginLevel 0 "Guest" 1 "User" 2 "Admin" ;
VAL_ 2578777089 ContactorControl_ContactorState 0 "OPEN" 1 "CLOSE" ;
VAL_ 2578777092 Statistics_Identifier 0 "Total Disharge" 1 "Total Charge" 2 "Total Discharge Energy" 3 "Total Charge Energy" 4 "Total Discharge Time" 5 "Total Charge Time" 6 "Total Distance" 7 "Master Clear Count" 8 "Max Discharge Current" 9 "Max Charge Current" 10 "Min Cell Voltage" 11 "Max Cell Voltage" 12 "Max Cell Voltage Difference" 13 "Min Pack Voltage" 14 "Max Pack Voltage" 15 "Min Cell Module Temperature" 16 "Max Cell Module Temperature" 17 "Max Cell Module Temperature Difference" 18 "BMS Starts Count" 19 "Under Voltage Protection Count" 20 "Over Voltage Protection Count" 21 "Discharge Over Current Protection Count" 22 "Charge Over Current Protection Count" 23 "Cell Module Over Heat Protection Count" 24 "Leakage Protection Count" 25 "No Cell Communication Protection Count" 26 "Low Voltage Power Reduction Count" 27 "High Current Power Reduction Count" 28 "High Cell Module Temp Power Reduction Count" 29 "Charger Connected Count" 30 "Charger Disconnected Count" 31 "Pre Heat Stage Count" 32 "Pre Charge Stage Count" 33 "Main Charge Stage Count" 34 "Balancing Stage Count" 35 "Charging Finished Count" 36 "Charging Error Count" 37 "Charging Retry Count" 38 "Trips Count" 39 "Charge Restarts Count" 40 "Cell Over Heat Protection Count" 41 "High Cell Temperature Power Reduction Count" 42 "Min Cell Temperature" 43 "Max Cell Temperature Count" 44 "Max Cell Temperature Difference" ;
VAL_ 2578777092 Statistics_DataType 0 "Statistics Value" 1 "Additional Value" 2 "Statistics Timestamp" ;
VAL_ 2578777093 Events_DataType 0 "Event Info " 1 "Event timestamp" ;
VAL_ 2578777093 Events_Data 0 "No event" 1 "BMS Started" 2 "Lost Communication To Cells" 3 "Established Communication To Cells" 4 "Cells Voltage Critically Low" 5 "Critical Low Voltage Recovered" 6 "Cells Voltage Critically High " 7 "Critical High Voltage Recovered" 8 "Discharge Current Critically High" 9 "Discharge Critically High Current Recovered" 10 "Charge Current Critically High" 11 "Charge Critically High Current Recovered" 12 "Cell Module Temperature Critically High" 13 "Critical High Cell Module Temperature Recovered" 14 "Leakage Detected" 15 "Leakage Recovered" 16 "Warning: Low Voltage - Reducing Power" 17 "Power Reduction Due To Low Voltage Recovered" 18 "Warning: High Current - Reducing Power" 19 "Power Reduction Due To High Current Recovered" 20 "Warning: High Cell Module Temperature - Reducing Power" 21 "Power Reduction Due To High Cell Module Temperature Recovered" 22 "Charger Connected" 23 "Charger Disconnected" 24 "Started Pre-Heating Stage" 25 "Started Pre-Charging Stage" 26 "Started Main-Charging Stage" 27 "Started Balancing Stage" 28 "Charging Finished" 29 "Charging Error Occured" 30 "Retrying Charging" 31 "Restarting Charging" 32 "Cell Temperature Critically High" 33 "Critically High Cell Temperature Recovered" 34 "Warning: High Cell Temperature - Reducing Power" 35 "Power Reduction Due To High Cell Temperature Recovered" ;
VAL_ 437 OverallParams_LastChargingError 0 "No Error" 1 "No Cell Communication" 2 "No Cell Communication 2" 3 "Maximum Charging Stage Duration Expired" 4 "Cell Communication Lost" 5 "Cannot Set Cell Module Balancing Threshold" 6 "Cell or Cell Module Temperature To High" 7 "Cell Commucation Lost 2" 8 "Number Of Cells Mismatch" 9 "Cell Over Voltage" 10 "Cell Protection Event Occurred" ;
VAL_ 437 OverallParams_ChrgStageDurat_LSB 0 "No Error" 1 "No Cell Communication" 2 "No Cell Communication 2" 3 "Maximum Charging Stage Duration Expired" 4 "Cell Communication Lost" 5 "Cannot Set Cell Module Balancing Threshold" 6 "Cell or Cell Module Temperature To High" 7 "Cell Commucation Lost 2" 8 "Number Of Cells Mismatch" 9 "Cell Over Voltage" 10 "Cell Protection Event Occurred" ;
VAL_ 437 OverallParams_ChargingStage 0 "OFF" 1 "ON" ;
VAL_ 437 OverallParams_ContactorPreCharge 0 "OFF" 1 "ON" ;
VAL_ 437 OverallParams_DCDC_Control 0 "OFF" 1 "ON" ;
VAL_ 437 OverallParams_ChargingInterlock 0 "OFF" 1 "ON" ;
VAL_ 437 OverallParams_PowerReduction 0 "OFF" 1 "ON" ;
VAL_ 437 OverallParams_BatteryFan 0 "OFF" 1 "ON" ;
VAL_ 437 OverallParams_BatteryContactor 0 "OFF" 1 "ON" ;
VAL_ 437 OverallParams_HeaterEnable 0 "OFF" 1 "ON" ;
VAL_ 437 OverallParams_ChargerEnable 0 "OFF" 1 "ON" ;
VAL_ 437 OverallParams_LeakageSensor 0 "OFF" 1 "ON" ;
VAL_ 437 OverallParams_FastCharge 0 "OFF" 1 "ON" ;
VAL_ 437 OverallParams_ChargerMains 0 "OFF" 1 "ON" ;
VAL_ 437 OverallParams_IgnitionKey 0 "OFF" 1 "ON" ;
VAL_ 566 ContactorControl_ContactorState 0 "OPEN" 1 "CLOSE" ;
VAL_ 570 Events_Data 0 "No event" 1 "BMS Started" 2 "Lost Communication To Cells" 3 "Established Communication To Cells" 4 "Cells Voltage Critically Low" 5 "Critical Low Voltage Recovered" 6 "Cells Voltage Critically High " 7 "Critical High Voltage Recovered" 8 "Discharge Current Critically High" 9 "Discharge Critically High Current Recovered" 10 "Charge Current Critically High" 11 "Charge Critically High Current Recovered" 12 "Cell Module Temperature Critically High" 13 "Critical High Cell Module Temperature Recovered" 14 "Leakage Detected" 15 "Leakage Recovered" 16 "Warning: Low Voltage - Reducing Power" 17 "Power Reduction Due To Low Voltage Recovered" 18 "Warning: High Current - Reducing Power" 19 "Power Reduction Due To High Current Recovered" 20 "Warning: High Cell Module Temperature - Reducing Power" 21 "Power Reduction Due To High Cell Module Temperature Recovered" 22 "Charger Connected" 23 "Charger Disconnected" 24 "Started Pre-Heating Stage" 25 "Started Pre-Charging Stage" 26 "Started Main-Charging Stage" 27 "Started Balancing Stage" 28 "Charging Finished" 29 "Charging Error Occured" 30 "Retrying Charging" 31 "Restarting Charging" 32 "Cell Temperature Critically High" 33 "Critically High Cell Temperature Recovered" 34 "Warning: High Cell Temperature - Reducing Power" 35 "Power Reduction Due To High Cell Temperature Recovered" ;
VAL_ 570 Events_DataType 0 "Event Info " 1 "Event timestamp" ;
VAL_ 567 LoginLevel 0 "Guest" 1 "User" 2 "Admin" ;
VAL_ 569 Statistics_DataType 0 "Statistics Value" 1 "Additional Value" 2 "Statistics Timestamp" ;
VAL_ 569 Statistics_Identifier 0 "Total Disharge" 1 "Total Charge" 2 "Total Discharge Energy" 3 "Total Charge Energy" 4 "Total Discharge Time" 5 "Total Charge Time" 6 "Total Distance" 7 "Master Clear Count" 8 "Max Discharge Current" 9 "Max Charge Current" 10 "Min Cell Voltage" 11 "Max Cell Voltage" 12 "Max Cell Voltage Difference" 13 "Min Pack Voltage" 14 "Max Pack Voltage" 15 "Min Cell Module Temperature" 16 "Max Cell Module Temperature" 17 "Max Cell Module Temperature Difference" 18 "BMS Starts Count" 19 "Under Voltage Protection Count" 20 "Over Voltage Protection Count" 21 "Discharge Over Current Protection Count" 22 "Charge Over Current Protection Count" 23 "Cell Module Over Heat Protection Count" 24 "Leakage Protection Count" 25 "No Cell Communication Protection Count" 26 "Low Voltage Power Reduction Count" 27 "High Current Power Reduction Count" 28 "High Cell Module Temp Power Reduction Count" 29 "Charger Connected Count" 30 "Charger Disconnected Count" 31 "Pre Heat Stage Count" 32 "Pre Charge Stage Count" 33 "Main Charge Stage Count" 34 "Balancing Stage Count" 35 "Charging Finished Count" 36 "Charging Error Count" 37 "Charging Retry Count" 38 "Trips Count" 39 "Charge Restarts Count" 40 "Cell Over Heat Protection Count" 41 "High Cell Temperature Power Reduction Count" 42 "Min Cell Temperature" 43 "Max Cell Temperature Count" 44 "Max Cell Temperature Difference" ;
VAL_ 1328 Neuro4_FirstByteFirstBit 0 "OPEN" 1 "CLOSE" ;
VAL_ 1328 Neuro4_ChargingStatus 0 "Not Charging" 1 "Charing In Progress" 2 "Charging Completed" 3 "Charging Fault" ;
